# DMPAC_TOP_MAIN_0_DMPAC_REGS_DMPAC_REGS_CFG_IP_MMRS register map
Vendor: Texas Instruments
Registers are 32-bit, access not given, reset values left out (the file's numbers can be read two ways) unless marked. A register's access mark holds for its fields unless they carry their own. Offsets are as the file gives them; [hi:lo] are bit positions; {n}, {i} and the like mark numbered series.

## DMPAC_TOP_MAIN_0_DMPAC_REGS_DMPAC_REGS_CFG_IP_MMRS (part 2 of 2)
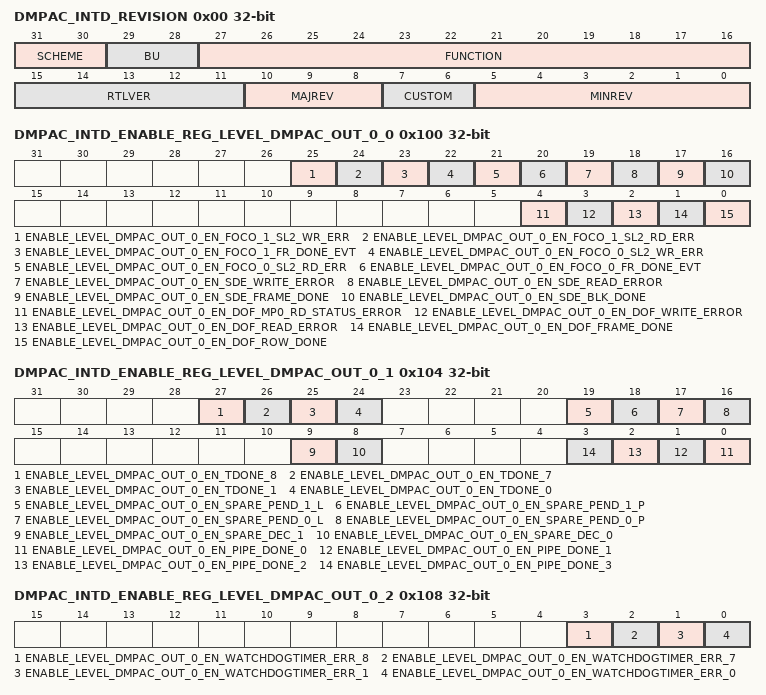
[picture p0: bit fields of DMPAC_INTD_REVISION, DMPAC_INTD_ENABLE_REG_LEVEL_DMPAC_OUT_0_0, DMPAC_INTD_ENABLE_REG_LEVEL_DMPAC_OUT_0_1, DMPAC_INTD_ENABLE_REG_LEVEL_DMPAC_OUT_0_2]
0x00 DMPAC_INTD_REVISION ro — Revision Register
  [31:30] SCHEME
  [29:28] BU
  [27:16] FUNCTION — Module ID
  [15:11] RTLVER — RTL revisions
  [10:8] MAJREV — MajorDMPAC_INTD_REVISION
  [7:6] CUSTOM — CustomDMPAC_INTD_REVISION
  [5:0] MINREV — MinorDMPAC_INTD_REVISION
0x10 DMPAC_INTD_EOI_REG rw — End of Interrupt Register The EOI register is used to re-trigger the pulse interrupt signal to ensure that any nested interrupt events are serviced. The software interrupt handler must write to the EOI register at the end of the current interrupt processing routine, so that new events can re-trigger the pulse interrupt signal again. For level interrupt signals the EOI register is not functional and must not be used.
  [7:0] EOI_VECTOR — End of Interrupt Vector
0x14 DMPAC_INTD_INTR_VECTOR_REG ro — Interrupt Vector Register
  [31:0] INTR_VECTOR
0x100 DMPAC_INTD_ENABLE_REG_LEVEL_DMPAC_OUT_0_0 — Enable Register 0
  [25] ENABLE_LEVEL_DMPAC_OUT_0_EN_FOCO_1_SL2_WR_ERR — Enable Set for level_dmpac_out_0_en_foco_1_sl2_wr_err (access RW1S)
  [24] ENABLE_LEVEL_DMPAC_OUT_0_EN_FOCO_1_SL2_RD_ERR — Enable Set for level_dmpac_out_0_en_foco_1_sl2_rd_err (access RW1S)
  [23] ENABLE_LEVEL_DMPAC_OUT_0_EN_FOCO_1_FR_DONE_EVT — Enable Set for level_dmpac_out_0_en_foco_1_fr_done_evt (access RW1S)
  [22] ENABLE_LEVEL_DMPAC_OUT_0_EN_FOCO_0_SL2_WR_ERR — Enable Set for level_dmpac_out_0_en_foco_0_sl2_wr_err (access RW1S)
  [21] ENABLE_LEVEL_DMPAC_OUT_0_EN_FOCO_0_SL2_RD_ERR — Enable Set for level_dmpac_out_0_en_foco_0_sl2_rd_err (access RW1S)
  [20] ENABLE_LEVEL_DMPAC_OUT_0_EN_FOCO_0_FR_DONE_EVT — Enable Set for level_dmpac_out_0_en_foco_0_fr_done_evt (access RW1S)
  [19] ENABLE_LEVEL_DMPAC_OUT_0_EN_SDE_WRITE_ERROR — Enable Set for level_dmpac_out_0_en_sde_write_error (access RW1S)
  [18] ENABLE_LEVEL_DMPAC_OUT_0_EN_SDE_READ_ERROR — Enable Set for level_dmpac_out_0_en_sde_read_error (access RW1S)
  [17] ENABLE_LEVEL_DMPAC_OUT_0_EN_SDE_FRAME_DONE — Enable Set for level_dmpac_out_0_en_sde_frame_done (access RW1S)
  [16] ENABLE_LEVEL_DMPAC_OUT_0_EN_SDE_BLK_DONE — Enable Set for level_dmpac_out_0_en_sde_blk_done (access RW1S)
  [4] ENABLE_LEVEL_DMPAC_OUT_0_EN_DOF_MP0_RD_STATUS_ERROR — Enable Set for level_dmpac_out_0_en_dof_mp0_rd_status_error (access RW1S)
  [3] ENABLE_LEVEL_DMPAC_OUT_0_EN_DOF_WRITE_ERROR — Enable Set for level_dmpac_out_0_en_dof_write_error (access RW1S)
  [2] ENABLE_LEVEL_DMPAC_OUT_0_EN_DOF_READ_ERROR — Enable Set for level_dmpac_out_0_en_dof_read_error (access RW1S)
  [1] ENABLE_LEVEL_DMPAC_OUT_0_EN_DOF_FRAME_DONE — Enable Set for level_dmpac_out_0_en_dof_frame_done (access RW1S)
  [0] ENABLE_LEVEL_DMPAC_OUT_0_EN_DOF_ROW_DONE — Enable Set for level_dmpac_out_0_en_dof_row_done (access RW1S)
0x104 DMPAC_INTD_ENABLE_REG_LEVEL_DMPAC_OUT_0_1 — Enable Register 1
  [27] ENABLE_LEVEL_DMPAC_OUT_0_EN_TDONE_8 — Enable Set for level_dmpac_out_0_en_tdone_8 (access RW1S)
  [26] ENABLE_LEVEL_DMPAC_OUT_0_EN_TDONE_7 — Enable Set for level_dmpac_out_0_en_tdone_7 (access RW1S)
  [25] ENABLE_LEVEL_DMPAC_OUT_0_EN_TDONE_1 — Enable Set for level_dmpac_out_0_en_tdone_1 (access RW1S)
  [24] ENABLE_LEVEL_DMPAC_OUT_0_EN_TDONE_0 — Enable Set for level_dmpac_out_0_en_tdone_0 (access RW1S)
  [19] ENABLE_LEVEL_DMPAC_OUT_0_EN_SPARE_PEND_1_L — Enable Set for level_dmpac_out_0_en_spare_pend_1_l (access RW1S)
  [18] ENABLE_LEVEL_DMPAC_OUT_0_EN_SPARE_PEND_1_P — Enable Set for level_dmpac_out_0_en_spare_pend_1_p (access RW1S)
  [17] ENABLE_LEVEL_DMPAC_OUT_0_EN_SPARE_PEND_0_L — Enable Set for level_dmpac_out_0_en_spare_pend_0_l (access RW1S)
  [16] ENABLE_LEVEL_DMPAC_OUT_0_EN_SPARE_PEND_0_P — Enable Set for level_dmpac_out_0_en_spare_pend_0_p (access RW1S)
  [9] ENABLE_LEVEL_DMPAC_OUT_0_EN_SPARE_DEC_1 — Enable Set for level_dmpac_out_0_en_spare_dec_1 (access RW1S)
  [8] ENABLE_LEVEL_DMPAC_OUT_0_EN_SPARE_DEC_0 — Enable Set for level_dmpac_out_0_en_spare_dec_0 (access RW1S)
  [n] ENABLE_LEVEL_DMPAC_OUT_0_EN_PIPE_DONE_{n} (n=0..3) — Enable Set for level_dmpac_out_0_en_pipe_done_{n} (access RW1S)
0x108 DMPAC_INTD_ENABLE_REG_LEVEL_DMPAC_OUT_0_2 — Enable Register 2
  [3] ENABLE_LEVEL_DMPAC_OUT_0_EN_WATCHDOGTIMER_ERR_8 — Enable Set for level_dmpac_out_0_en_watchdogtimer_err_8 (access RW1S)
  [2] ENABLE_LEVEL_DMPAC_OUT_0_EN_WATCHDOGTIMER_ERR_7 — Enable Set for level_dmpac_out_0_en_watchdogtimer_err_7 (access RW1S)
  [1] ENABLE_LEVEL_DMPAC_OUT_0_EN_WATCHDOGTIMER_ERR_1 — Enable Set for level_dmpac_out_0_en_watchdogtimer_err_1 (access RW1S)
  [0] ENABLE_LEVEL_DMPAC_OUT_0_EN_WATCHDOGTIMER_ERR_0 — Enable Set for level_dmpac_out_0_en_watchdogtimer_err_0 (access RW1S)
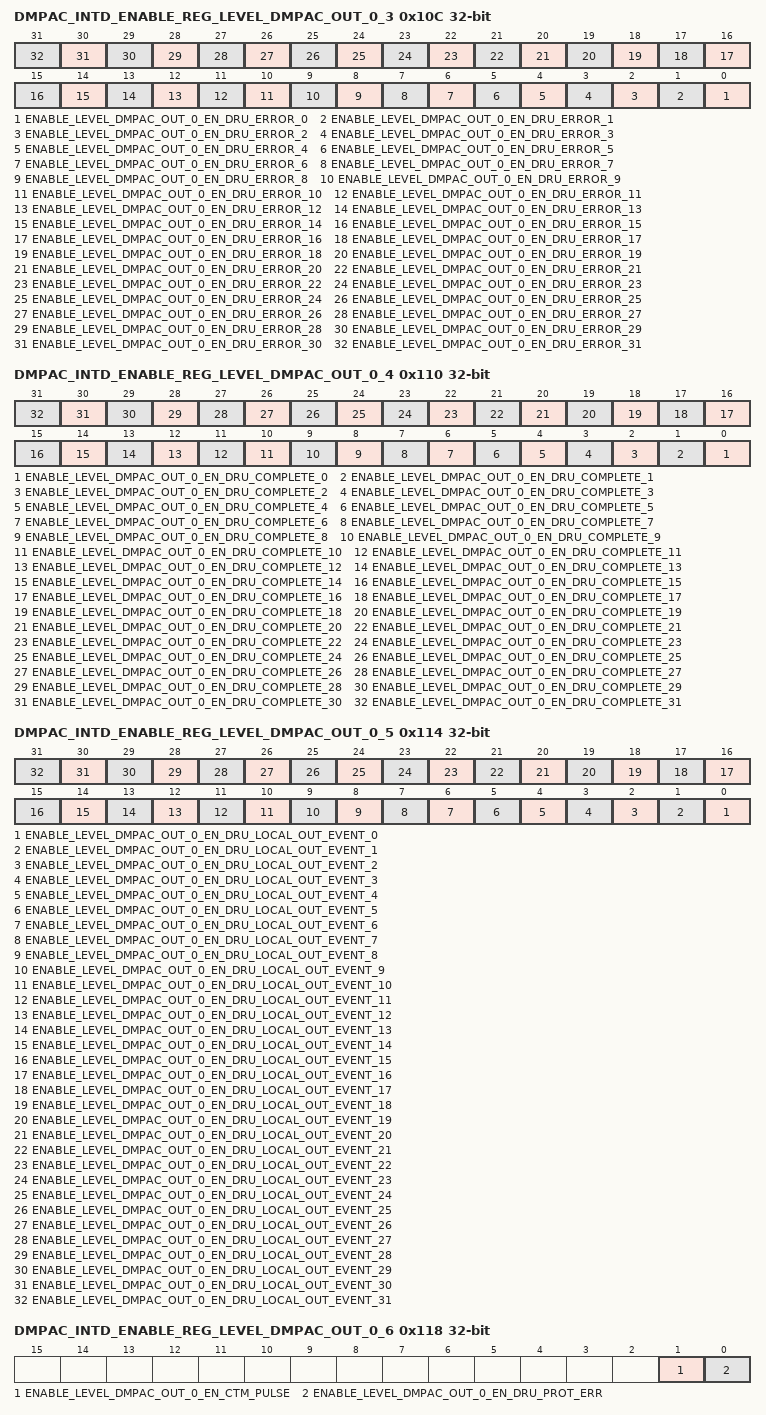
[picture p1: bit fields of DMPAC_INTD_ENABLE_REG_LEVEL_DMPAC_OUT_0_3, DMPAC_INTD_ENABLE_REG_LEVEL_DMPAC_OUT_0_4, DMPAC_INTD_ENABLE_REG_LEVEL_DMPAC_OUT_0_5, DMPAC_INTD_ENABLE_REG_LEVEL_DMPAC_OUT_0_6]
0x10C DMPAC_INTD_ENABLE_REG_LEVEL_DMPAC_OUT_0_3 — Enable Register 3
  [n] ENABLE_LEVEL_DMPAC_OUT_0_EN_DRU_ERROR_{n} (n=0..31) — Enable Set for level_dmpac_out_0_en_dru_error_{n} (access RW1S)
0x110 DMPAC_INTD_ENABLE_REG_LEVEL_DMPAC_OUT_0_4 — Enable Register 4
  [n] ENABLE_LEVEL_DMPAC_OUT_0_EN_DRU_COMPLETE_{n} (n=0..31) — Enable Set for level_dmpac_out_0_en_dru_complete_{n} (access RW1S)
0x114 DMPAC_INTD_ENABLE_REG_LEVEL_DMPAC_OUT_0_5 — Enable Register 5
  [n] ENABLE_LEVEL_DMPAC_OUT_0_EN_DRU_LOCAL_OUT_EVENT_{n} (n=0..31) — Enable Set for level_dmpac_out_0_en_dru_local_out_event_{n} (access RW1S)
0x118 DMPAC_INTD_ENABLE_REG_LEVEL_DMPAC_OUT_0_6 — Enable Register 6
  [1] ENABLE_LEVEL_DMPAC_OUT_0_EN_CTM_PULSE — Enable Set for level_dmpac_out_0_en_ctm_pulse (access RW1S)
  [0] ENABLE_LEVEL_DMPAC_OUT_0_EN_DRU_PROT_ERR — Enable Set for level_dmpac_out_0_en_dru_prot_err (access RW1S)
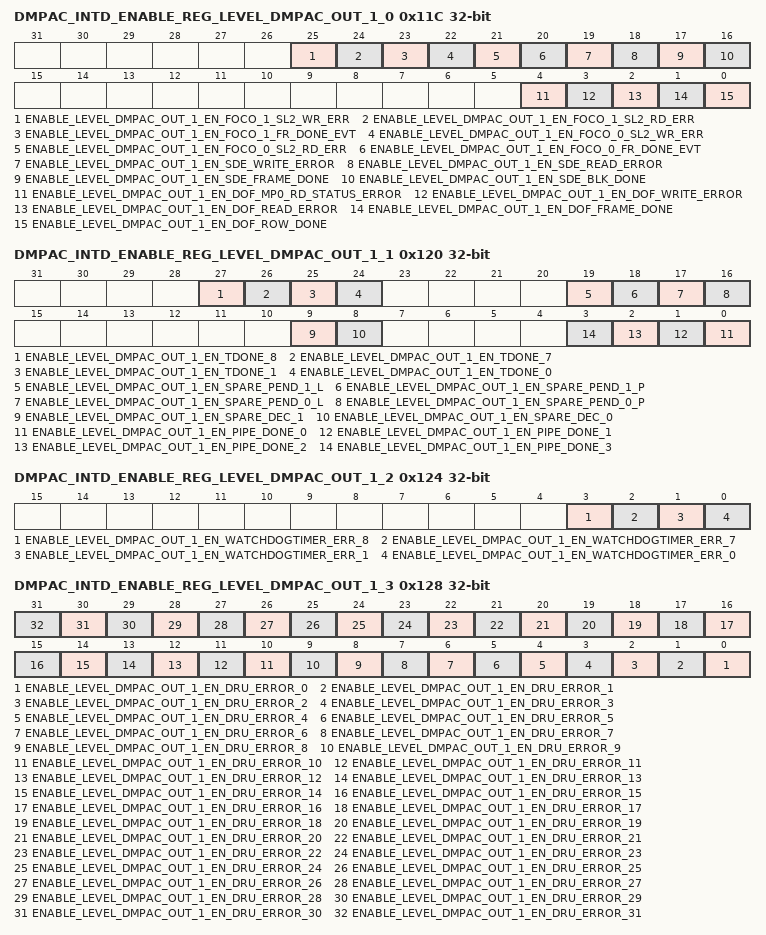
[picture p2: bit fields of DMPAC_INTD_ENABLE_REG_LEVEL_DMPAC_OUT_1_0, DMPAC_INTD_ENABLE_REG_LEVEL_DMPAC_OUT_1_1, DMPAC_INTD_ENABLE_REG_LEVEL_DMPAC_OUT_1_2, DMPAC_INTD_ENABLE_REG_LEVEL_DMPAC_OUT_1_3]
0x11C DMPAC_INTD_ENABLE_REG_LEVEL_DMPAC_OUT_1_0 — Enable Register 7
  [25] ENABLE_LEVEL_DMPAC_OUT_1_EN_FOCO_1_SL2_WR_ERR — Enable Set for level_dmpac_out_1_en_foco_1_sl2_wr_err (access RW1S)
  [24] ENABLE_LEVEL_DMPAC_OUT_1_EN_FOCO_1_SL2_RD_ERR — Enable Set for level_dmpac_out_1_en_foco_1_sl2_rd_err (access RW1S)
  [23] ENABLE_LEVEL_DMPAC_OUT_1_EN_FOCO_1_FR_DONE_EVT — Enable Set for level_dmpac_out_1_en_foco_1_fr_done_evt (access RW1S)
  [22] ENABLE_LEVEL_DMPAC_OUT_1_EN_FOCO_0_SL2_WR_ERR — Enable Set for level_dmpac_out_1_en_foco_0_sl2_wr_err (access RW1S)
  [21] ENABLE_LEVEL_DMPAC_OUT_1_EN_FOCO_0_SL2_RD_ERR — Enable Set for level_dmpac_out_1_en_foco_0_sl2_rd_err (access RW1S)
  [20] ENABLE_LEVEL_DMPAC_OUT_1_EN_FOCO_0_FR_DONE_EVT — Enable Set for level_dmpac_out_1_en_foco_0_fr_done_evt (access RW1S)
  [19] ENABLE_LEVEL_DMPAC_OUT_1_EN_SDE_WRITE_ERROR — Enable Set for level_dmpac_out_1_en_sde_write_error (access RW1S)
  [18] ENABLE_LEVEL_DMPAC_OUT_1_EN_SDE_READ_ERROR — Enable Set for level_dmpac_out_1_en_sde_read_error (access RW1S)
  [17] ENABLE_LEVEL_DMPAC_OUT_1_EN_SDE_FRAME_DONE — Enable Set for level_dmpac_out_1_en_sde_frame_done (access RW1S)
  [16] ENABLE_LEVEL_DMPAC_OUT_1_EN_SDE_BLK_DONE — Enable Set for level_dmpac_out_1_en_sde_blk_done (access RW1S)
  [4] ENABLE_LEVEL_DMPAC_OUT_1_EN_DOF_MP0_RD_STATUS_ERROR — Enable Set for level_dmpac_out_1_en_dof_mp0_rd_status_error (access RW1S)
  [3] ENABLE_LEVEL_DMPAC_OUT_1_EN_DOF_WRITE_ERROR — Enable Set for level_dmpac_out_1_en_dof_write_error (access RW1S)
  [2] ENABLE_LEVEL_DMPAC_OUT_1_EN_DOF_READ_ERROR — Enable Set for level_dmpac_out_1_en_dof_read_error (access RW1S)
  [1] ENABLE_LEVEL_DMPAC_OUT_1_EN_DOF_FRAME_DONE — Enable Set for level_dmpac_out_1_en_dof_frame_done (access RW1S)
  [0] ENABLE_LEVEL_DMPAC_OUT_1_EN_DOF_ROW_DONE — Enable Set for level_dmpac_out_1_en_dof_row_done (access RW1S)
0x120 DMPAC_INTD_ENABLE_REG_LEVEL_DMPAC_OUT_1_1 — Enable Register 8
  [27] ENABLE_LEVEL_DMPAC_OUT_1_EN_TDONE_8 — Enable Set for level_dmpac_out_1_en_tdone_8 (access RW1S)
  [26] ENABLE_LEVEL_DMPAC_OUT_1_EN_TDONE_7 — Enable Set for level_dmpac_out_1_en_tdone_7 (access RW1S)
  [25] ENABLE_LEVEL_DMPAC_OUT_1_EN_TDONE_1 — Enable Set for level_dmpac_out_1_en_tdone_1 (access RW1S)
  [24] ENABLE_LEVEL_DMPAC_OUT_1_EN_TDONE_0 — Enable Set for level_dmpac_out_1_en_tdone_0 (access RW1S)
  [19] ENABLE_LEVEL_DMPAC_OUT_1_EN_SPARE_PEND_1_L — Enable Set for level_dmpac_out_1_en_spare_pend_1_l (access RW1S)
  [18] ENABLE_LEVEL_DMPAC_OUT_1_EN_SPARE_PEND_1_P — Enable Set for level_dmpac_out_1_en_spare_pend_1_p (access RW1S)
  [17] ENABLE_LEVEL_DMPAC_OUT_1_EN_SPARE_PEND_0_L — Enable Set for level_dmpac_out_1_en_spare_pend_0_l (access RW1S)
  [16] ENABLE_LEVEL_DMPAC_OUT_1_EN_SPARE_PEND_0_P — Enable Set for level_dmpac_out_1_en_spare_pend_0_p (access RW1S)
  [9] ENABLE_LEVEL_DMPAC_OUT_1_EN_SPARE_DEC_1 — Enable Set for level_dmpac_out_1_en_spare_dec_1 (access RW1S)
  [8] ENABLE_LEVEL_DMPAC_OUT_1_EN_SPARE_DEC_0 — Enable Set for level_dmpac_out_1_en_spare_dec_0 (access RW1S)
  [n] ENABLE_LEVEL_DMPAC_OUT_1_EN_PIPE_DONE_{n} (n=0..3) — Enable Set for level_dmpac_out_1_en_pipe_done_{n} (access RW1S)
0x124 DMPAC_INTD_ENABLE_REG_LEVEL_DMPAC_OUT_1_2 — Enable Register 9
  [3] ENABLE_LEVEL_DMPAC_OUT_1_EN_WATCHDOGTIMER_ERR_8 — Enable Set for level_dmpac_out_1_en_watchdogtimer_err_8 (access RW1S)
  [2] ENABLE_LEVEL_DMPAC_OUT_1_EN_WATCHDOGTIMER_ERR_7 — Enable Set for level_dmpac_out_1_en_watchdogtimer_err_7 (access RW1S)
  [1] ENABLE_LEVEL_DMPAC_OUT_1_EN_WATCHDOGTIMER_ERR_1 — Enable Set for level_dmpac_out_1_en_watchdogtimer_err_1 (access RW1S)
  [0] ENABLE_LEVEL_DMPAC_OUT_1_EN_WATCHDOGTIMER_ERR_0 — Enable Set for level_dmpac_out_1_en_watchdogtimer_err_0 (access RW1S)
0x128 DMPAC_INTD_ENABLE_REG_LEVEL_DMPAC_OUT_1_3 — Enable Register 10
  [n] ENABLE_LEVEL_DMPAC_OUT_1_EN_DRU_ERROR_{n} (n=0..31) — Enable Set for level_dmpac_out_1_en_dru_error_{n} (access RW1S)
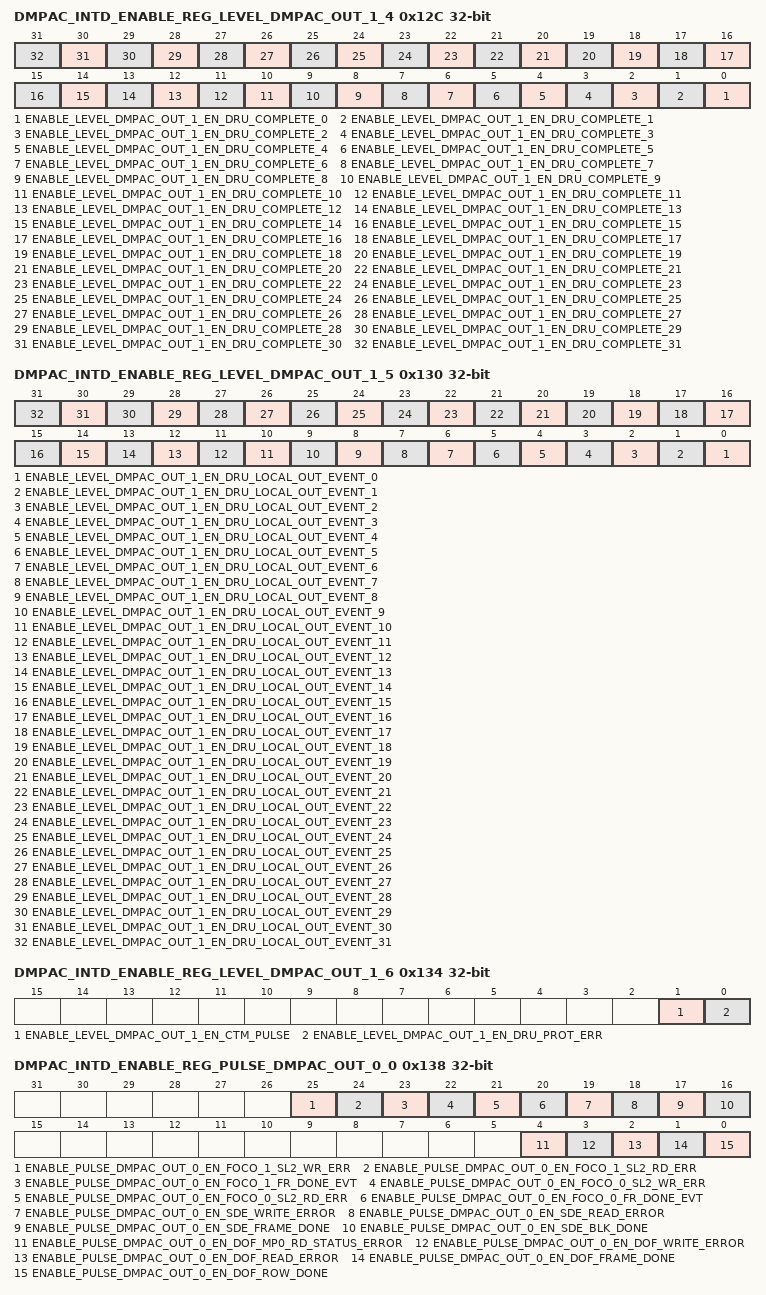
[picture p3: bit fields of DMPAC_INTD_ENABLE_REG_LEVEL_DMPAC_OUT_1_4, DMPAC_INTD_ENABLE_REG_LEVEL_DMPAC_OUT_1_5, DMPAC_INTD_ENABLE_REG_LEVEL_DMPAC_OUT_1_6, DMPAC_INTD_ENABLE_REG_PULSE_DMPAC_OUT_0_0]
0x12C DMPAC_INTD_ENABLE_REG_LEVEL_DMPAC_OUT_1_4 — Enable Register 11
  [n] ENABLE_LEVEL_DMPAC_OUT_1_EN_DRU_COMPLETE_{n} (n=0..31) — Enable Set for level_dmpac_out_1_en_dru_complete_{n} (access RW1S)
0x130 DMPAC_INTD_ENABLE_REG_LEVEL_DMPAC_OUT_1_5 — Enable Register 12
  [n] ENABLE_LEVEL_DMPAC_OUT_1_EN_DRU_LOCAL_OUT_EVENT_{n} (n=0..31) — Enable Set for level_dmpac_out_1_en_dru_local_out_event_{n} (access RW1S)
0x134 DMPAC_INTD_ENABLE_REG_LEVEL_DMPAC_OUT_1_6 — Enable Register 13
  [1] ENABLE_LEVEL_DMPAC_OUT_1_EN_CTM_PULSE — Enable Set for level_dmpac_out_1_en_ctm_pulse (access RW1S)
  [0] ENABLE_LEVEL_DMPAC_OUT_1_EN_DRU_PROT_ERR — Enable Set for level_dmpac_out_1_en_dru_prot_err (access RW1S)
0x138 DMPAC_INTD_ENABLE_REG_PULSE_DMPAC_OUT_0_0 — Enable Register 14
  [25] ENABLE_PULSE_DMPAC_OUT_0_EN_FOCO_1_SL2_WR_ERR — Enable Set for pulse_dmpac_out_0_en_foco_1_sl2_wr_err (access RW1S)
  [24] ENABLE_PULSE_DMPAC_OUT_0_EN_FOCO_1_SL2_RD_ERR — Enable Set for pulse_dmpac_out_0_en_foco_1_sl2_rd_err (access RW1S)
  [23] ENABLE_PULSE_DMPAC_OUT_0_EN_FOCO_1_FR_DONE_EVT — Enable Set for pulse_dmpac_out_0_en_foco_1_fr_done_evt (access RW1S)
  [22] ENABLE_PULSE_DMPAC_OUT_0_EN_FOCO_0_SL2_WR_ERR — Enable Set for pulse_dmpac_out_0_en_foco_0_sl2_wr_err (access RW1S)
  [21] ENABLE_PULSE_DMPAC_OUT_0_EN_FOCO_0_SL2_RD_ERR — Enable Set for pulse_dmpac_out_0_en_foco_0_sl2_rd_err (access RW1S)
  [20] ENABLE_PULSE_DMPAC_OUT_0_EN_FOCO_0_FR_DONE_EVT — Enable Set for pulse_dmpac_out_0_en_foco_0_fr_done_evt (access RW1S)
  [19] ENABLE_PULSE_DMPAC_OUT_0_EN_SDE_WRITE_ERROR — Enable Set for pulse_dmpac_out_0_en_sde_write_error (access RW1S)
  [18] ENABLE_PULSE_DMPAC_OUT_0_EN_SDE_READ_ERROR — Enable Set for pulse_dmpac_out_0_en_sde_read_error (access RW1S)
  [17] ENABLE_PULSE_DMPAC_OUT_0_EN_SDE_FRAME_DONE — Enable Set for pulse_dmpac_out_0_en_sde_frame_done (access RW1S)
  [16] ENABLE_PULSE_DMPAC_OUT_0_EN_SDE_BLK_DONE — Enable Set for pulse_dmpac_out_0_en_sde_blk_done (access RW1S)
  [4] ENABLE_PULSE_DMPAC_OUT_0_EN_DOF_MP0_RD_STATUS_ERROR — Enable Set for pulse_dmpac_out_0_en_dof_mp0_rd_status_error (access RW1S)
  [3] ENABLE_PULSE_DMPAC_OUT_0_EN_DOF_WRITE_ERROR — Enable Set for pulse_dmpac_out_0_en_dof_write_error (access RW1S)
  [2] ENABLE_PULSE_DMPAC_OUT_0_EN_DOF_READ_ERROR — Enable Set for pulse_dmpac_out_0_en_dof_read_error (access RW1S)
  [1] ENABLE_PULSE_DMPAC_OUT_0_EN_DOF_FRAME_DONE — Enable Set for pulse_dmpac_out_0_en_dof_frame_done (access RW1S)
  [0] ENABLE_PULSE_DMPAC_OUT_0_EN_DOF_ROW_DONE — Enable Set for pulse_dmpac_out_0_en_dof_row_done (access RW1S)
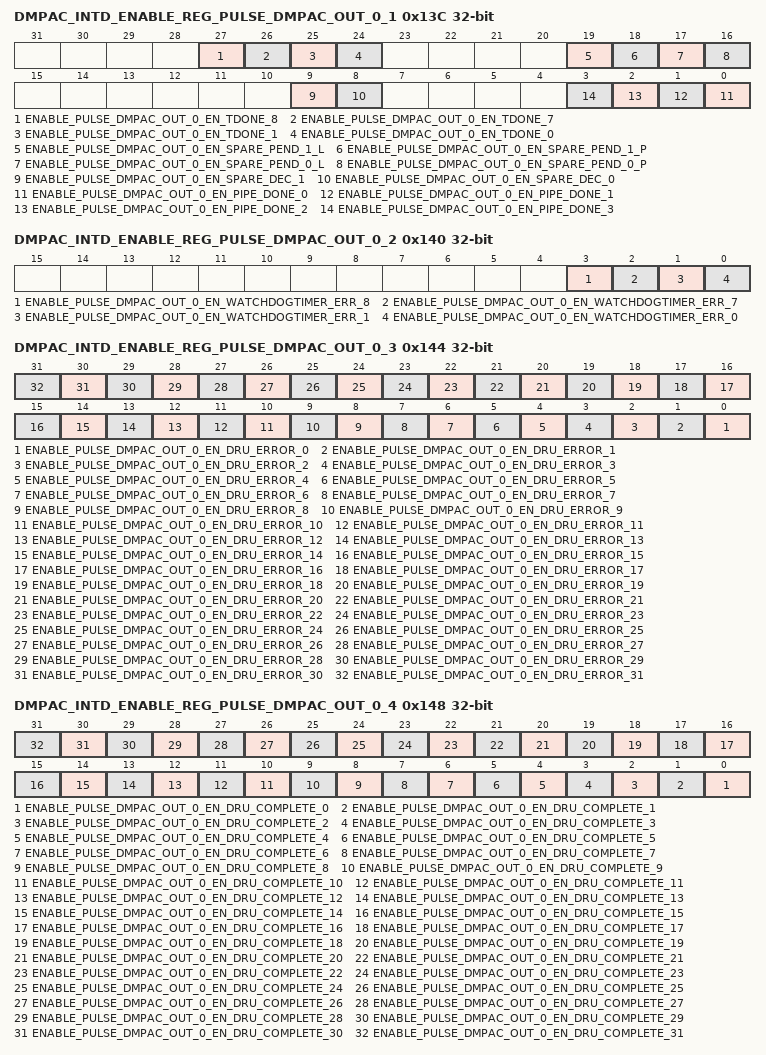
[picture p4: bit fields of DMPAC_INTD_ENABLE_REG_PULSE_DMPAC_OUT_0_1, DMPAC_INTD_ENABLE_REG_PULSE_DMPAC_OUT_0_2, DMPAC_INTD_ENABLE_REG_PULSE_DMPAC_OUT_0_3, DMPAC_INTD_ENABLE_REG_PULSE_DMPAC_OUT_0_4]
0x13C DMPAC_INTD_ENABLE_REG_PULSE_DMPAC_OUT_0_1 — Enable Register 15
  [27] ENABLE_PULSE_DMPAC_OUT_0_EN_TDONE_8 — Enable Set for pulse_dmpac_out_0_en_tdone_8 (access RW1S)
  [26] ENABLE_PULSE_DMPAC_OUT_0_EN_TDONE_7 — Enable Set for pulse_dmpac_out_0_en_tdone_7 (access RW1S)
  [25] ENABLE_PULSE_DMPAC_OUT_0_EN_TDONE_1 — Enable Set for pulse_dmpac_out_0_en_tdone_1 (access RW1S)
  [24] ENABLE_PULSE_DMPAC_OUT_0_EN_TDONE_0 — Enable Set for pulse_dmpac_out_0_en_tdone_0 (access RW1S)
  [19] ENABLE_PULSE_DMPAC_OUT_0_EN_SPARE_PEND_1_L — Enable Set for pulse_dmpac_out_0_en_spare_pend_1_l (access RW1S)
  [18] ENABLE_PULSE_DMPAC_OUT_0_EN_SPARE_PEND_1_P — Enable Set for pulse_dmpac_out_0_en_spare_pend_1_p (access RW1S)
  [17] ENABLE_PULSE_DMPAC_OUT_0_EN_SPARE_PEND_0_L — Enable Set for pulse_dmpac_out_0_en_spare_pend_0_l (access RW1S)
  [16] ENABLE_PULSE_DMPAC_OUT_0_EN_SPARE_PEND_0_P — Enable Set for pulse_dmpac_out_0_en_spare_pend_0_p (access RW1S)
  [9] ENABLE_PULSE_DMPAC_OUT_0_EN_SPARE_DEC_1 — Enable Set for pulse_dmpac_out_0_en_spare_dec_1 (access RW1S)
  [8] ENABLE_PULSE_DMPAC_OUT_0_EN_SPARE_DEC_0 — Enable Set for pulse_dmpac_out_0_en_spare_dec_0 (access RW1S)
  [n] ENABLE_PULSE_DMPAC_OUT_0_EN_PIPE_DONE_{n} (n=0..3) — Enable Set for pulse_dmpac_out_0_en_pipe_done_{n} (access RW1S)
0x140 DMPAC_INTD_ENABLE_REG_PULSE_DMPAC_OUT_0_2 — Enable Register 16
  [3] ENABLE_PULSE_DMPAC_OUT_0_EN_WATCHDOGTIMER_ERR_8 — Enable Set for pulse_dmpac_out_0_en_watchdogtimer_err_8 (access RW1S)
  [2] ENABLE_PULSE_DMPAC_OUT_0_EN_WATCHDOGTIMER_ERR_7 — Enable Set for pulse_dmpac_out_0_en_watchdogtimer_err_7 (access RW1S)
  [1] ENABLE_PULSE_DMPAC_OUT_0_EN_WATCHDOGTIMER_ERR_1 — Enable Set for pulse_dmpac_out_0_en_watchdogtimer_err_1 (access RW1S)
  [0] ENABLE_PULSE_DMPAC_OUT_0_EN_WATCHDOGTIMER_ERR_0 — Enable Set for pulse_dmpac_out_0_en_watchdogtimer_err_0 (access RW1S)
0x144 DMPAC_INTD_ENABLE_REG_PULSE_DMPAC_OUT_0_3 — Enable Register 17
  [n] ENABLE_PULSE_DMPAC_OUT_0_EN_DRU_ERROR_{n} (n=0..31) — Enable Set for pulse_dmpac_out_0_en_dru_error_{n} (access RW1S)
0x148 DMPAC_INTD_ENABLE_REG_PULSE_DMPAC_OUT_0_4 — Enable Register 18
  [n] ENABLE_PULSE_DMPAC_OUT_0_EN_DRU_COMPLETE_{n} (n=0..31) — Enable Set for pulse_dmpac_out_0_en_dru_complete_{n} (access RW1S)
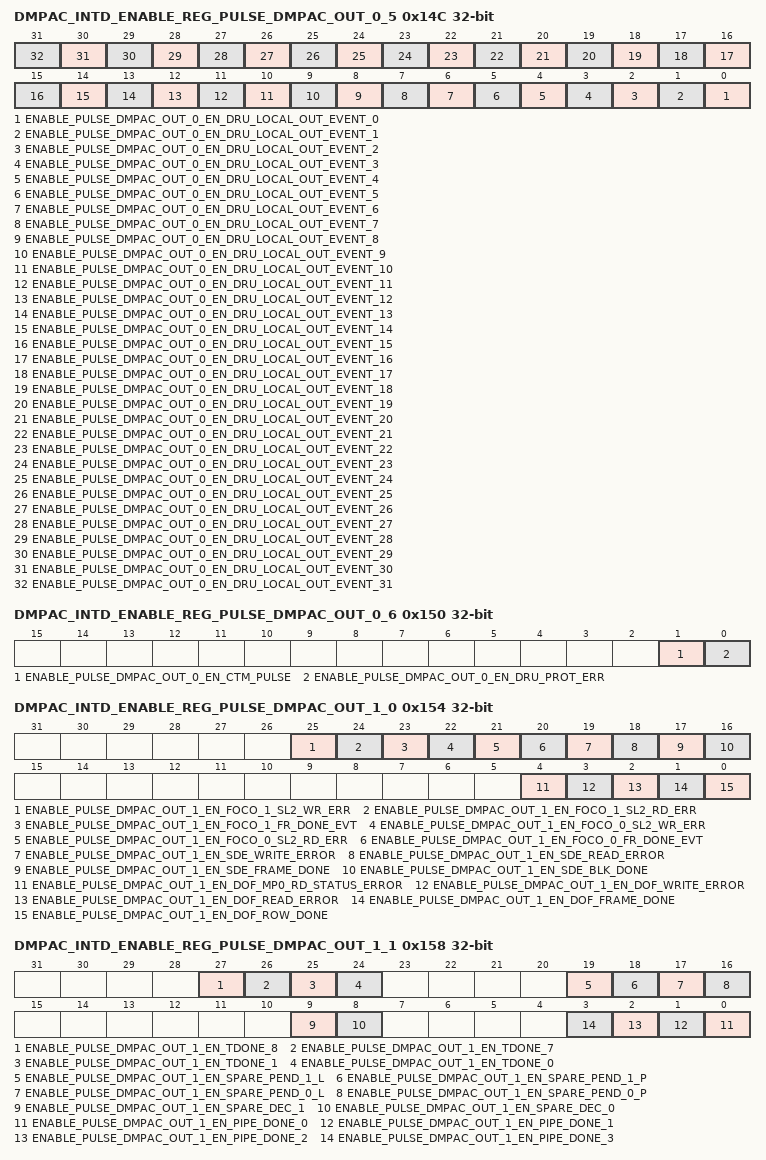
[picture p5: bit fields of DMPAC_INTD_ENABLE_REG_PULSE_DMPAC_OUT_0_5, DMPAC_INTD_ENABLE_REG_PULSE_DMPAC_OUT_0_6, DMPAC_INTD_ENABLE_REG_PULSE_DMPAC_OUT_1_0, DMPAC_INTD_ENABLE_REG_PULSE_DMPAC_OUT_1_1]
0x14C DMPAC_INTD_ENABLE_REG_PULSE_DMPAC_OUT_0_5 — Enable Register 19
  [n] ENABLE_PULSE_DMPAC_OUT_0_EN_DRU_LOCAL_OUT_EVENT_{n} (n=0..31) — Enable Set for pulse_dmpac_out_0_en_dru_local_out_event_{n} (access RW1S)
0x150 DMPAC_INTD_ENABLE_REG_PULSE_DMPAC_OUT_0_6 — Enable Register 20
  [1] ENABLE_PULSE_DMPAC_OUT_0_EN_CTM_PULSE — Enable Set for pulse_dmpac_out_0_en_ctm_pulse (access RW1S)
  [0] ENABLE_PULSE_DMPAC_OUT_0_EN_DRU_PROT_ERR — Enable Set for pulse_dmpac_out_0_en_dru_prot_err (access RW1S)
0x154 DMPAC_INTD_ENABLE_REG_PULSE_DMPAC_OUT_1_0 — Enable Register 21
  [25] ENABLE_PULSE_DMPAC_OUT_1_EN_FOCO_1_SL2_WR_ERR — Enable Set for pulse_dmpac_out_1_en_foco_1_sl2_wr_err (access RW1S)
  [24] ENABLE_PULSE_DMPAC_OUT_1_EN_FOCO_1_SL2_RD_ERR — Enable Set for pulse_dmpac_out_1_en_foco_1_sl2_rd_err (access RW1S)
  [23] ENABLE_PULSE_DMPAC_OUT_1_EN_FOCO_1_FR_DONE_EVT — Enable Set for pulse_dmpac_out_1_en_foco_1_fr_done_evt (access RW1S)
  [22] ENABLE_PULSE_DMPAC_OUT_1_EN_FOCO_0_SL2_WR_ERR — Enable Set for pulse_dmpac_out_1_en_foco_0_sl2_wr_err (access RW1S)
  [21] ENABLE_PULSE_DMPAC_OUT_1_EN_FOCO_0_SL2_RD_ERR — Enable Set for pulse_dmpac_out_1_en_foco_0_sl2_rd_err (access RW1S)
  [20] ENABLE_PULSE_DMPAC_OUT_1_EN_FOCO_0_FR_DONE_EVT — Enable Set for pulse_dmpac_out_1_en_foco_0_fr_done_evt (access RW1S)
  [19] ENABLE_PULSE_DMPAC_OUT_1_EN_SDE_WRITE_ERROR — Enable Set for pulse_dmpac_out_1_en_sde_write_error (access RW1S)
  [18] ENABLE_PULSE_DMPAC_OUT_1_EN_SDE_READ_ERROR — Enable Set for pulse_dmpac_out_1_en_sde_read_error (access RW1S)
  [17] ENABLE_PULSE_DMPAC_OUT_1_EN_SDE_FRAME_DONE — Enable Set for pulse_dmpac_out_1_en_sde_frame_done (access RW1S)
  [16] ENABLE_PULSE_DMPAC_OUT_1_EN_SDE_BLK_DONE — Enable Set for pulse_dmpac_out_1_en_sde_blk_done (access RW1S)
  [4] ENABLE_PULSE_DMPAC_OUT_1_EN_DOF_MP0_RD_STATUS_ERROR — Enable Set for pulse_dmpac_out_1_en_dof_mp0_rd_status_error (access RW1S)
  [3] ENABLE_PULSE_DMPAC_OUT_1_EN_DOF_WRITE_ERROR — Enable Set for pulse_dmpac_out_1_en_dof_write_error (access RW1S)
  [2] ENABLE_PULSE_DMPAC_OUT_1_EN_DOF_READ_ERROR — Enable Set for pulse_dmpac_out_1_en_dof_read_error (access RW1S)
  [1] ENABLE_PULSE_DMPAC_OUT_1_EN_DOF_FRAME_DONE — Enable Set for pulse_dmpac_out_1_en_dof_frame_done (access RW1S)
  [0] ENABLE_PULSE_DMPAC_OUT_1_EN_DOF_ROW_DONE — Enable Set for pulse_dmpac_out_1_en_dof_row_done (access RW1S)
0x158 DMPAC_INTD_ENABLE_REG_PULSE_DMPAC_OUT_1_1 — Enable Register 22
  [27] ENABLE_PULSE_DMPAC_OUT_1_EN_TDONE_8 — Enable Set for pulse_dmpac_out_1_en_tdone_8 (access RW1S)
  [26] ENABLE_PULSE_DMPAC_OUT_1_EN_TDONE_7 — Enable Set for pulse_dmpac_out_1_en_tdone_7 (access RW1S)
  [25] ENABLE_PULSE_DMPAC_OUT_1_EN_TDONE_1 — Enable Set for pulse_dmpac_out_1_en_tdone_1 (access RW1S)
  [24] ENABLE_PULSE_DMPAC_OUT_1_EN_TDONE_0 — Enable Set for pulse_dmpac_out_1_en_tdone_0 (access RW1S)
  [19] ENABLE_PULSE_DMPAC_OUT_1_EN_SPARE_PEND_1_L — Enable Set for pulse_dmpac_out_1_en_spare_pend_1_l (access RW1S)
  [18] ENABLE_PULSE_DMPAC_OUT_1_EN_SPARE_PEND_1_P — Enable Set for pulse_dmpac_out_1_en_spare_pend_1_p (access RW1S)
  [17] ENABLE_PULSE_DMPAC_OUT_1_EN_SPARE_PEND_0_L — Enable Set for pulse_dmpac_out_1_en_spare_pend_0_l (access RW1S)
  [16] ENABLE_PULSE_DMPAC_OUT_1_EN_SPARE_PEND_0_P — Enable Set for pulse_dmpac_out_1_en_spare_pend_0_p (access RW1S)
  [9] ENABLE_PULSE_DMPAC_OUT_1_EN_SPARE_DEC_1 — Enable Set for pulse_dmpac_out_1_en_spare_dec_1 (access RW1S)
  [8] ENABLE_PULSE_DMPAC_OUT_1_EN_SPARE_DEC_0 — Enable Set for pulse_dmpac_out_1_en_spare_dec_0 (access RW1S)
  [n] ENABLE_PULSE_DMPAC_OUT_1_EN_PIPE_DONE_{n} (n=0..3) — Enable Set for pulse_dmpac_out_1_en_pipe_done_{n} (access RW1S)
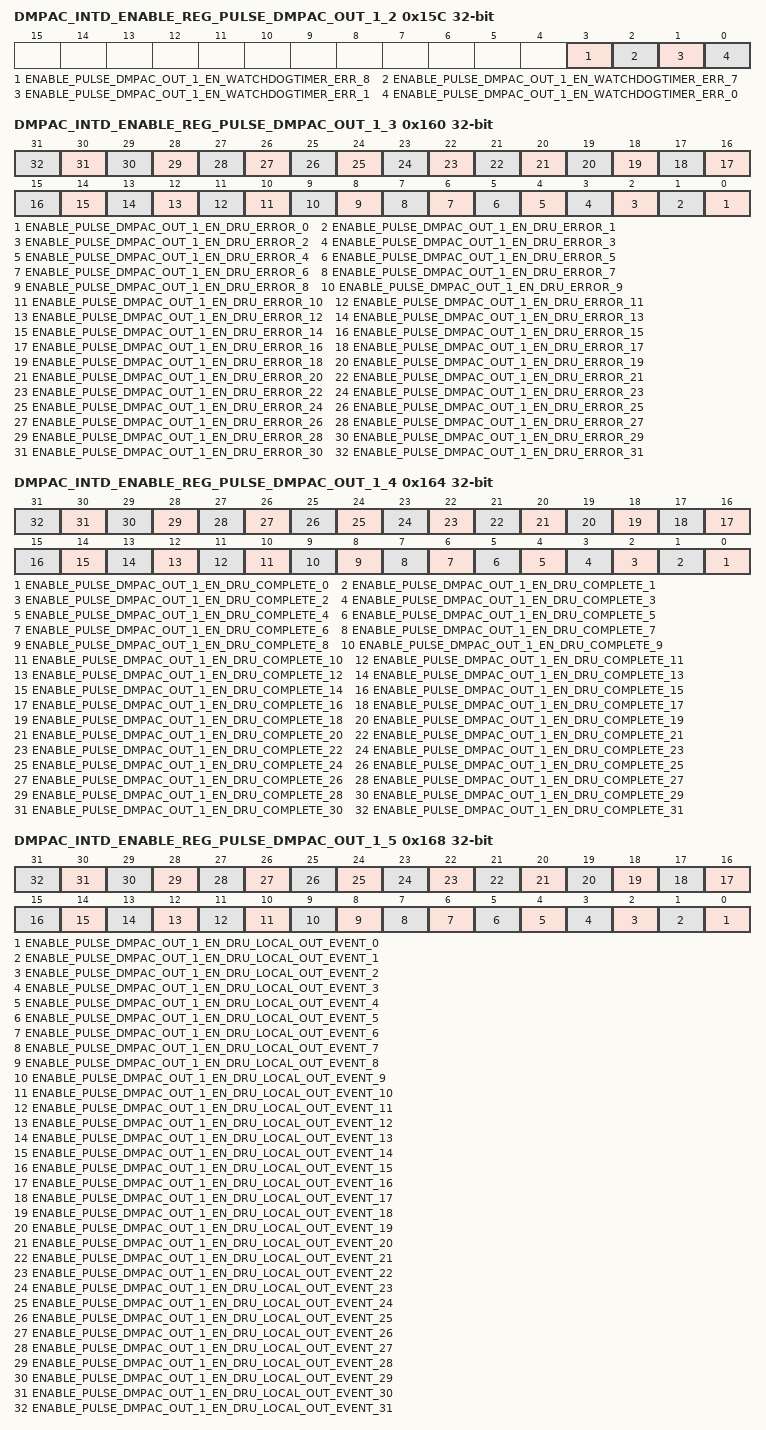
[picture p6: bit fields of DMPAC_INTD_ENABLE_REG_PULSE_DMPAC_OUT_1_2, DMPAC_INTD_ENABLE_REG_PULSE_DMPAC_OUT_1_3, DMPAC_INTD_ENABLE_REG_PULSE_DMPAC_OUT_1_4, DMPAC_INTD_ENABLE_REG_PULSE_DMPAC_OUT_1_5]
0x15C DMPAC_INTD_ENABLE_REG_PULSE_DMPAC_OUT_1_2 — Enable Register 23
  [3] ENABLE_PULSE_DMPAC_OUT_1_EN_WATCHDOGTIMER_ERR_8 — Enable Set for pulse_dmpac_out_1_en_watchdogtimer_err_8 (access RW1S)
  [2] ENABLE_PULSE_DMPAC_OUT_1_EN_WATCHDOGTIMER_ERR_7 — Enable Set for pulse_dmpac_out_1_en_watchdogtimer_err_7 (access RW1S)
  [1] ENABLE_PULSE_DMPAC_OUT_1_EN_WATCHDOGTIMER_ERR_1 — Enable Set for pulse_dmpac_out_1_en_watchdogtimer_err_1 (access RW1S)
  [0] ENABLE_PULSE_DMPAC_OUT_1_EN_WATCHDOGTIMER_ERR_0 — Enable Set for pulse_dmpac_out_1_en_watchdogtimer_err_0 (access RW1S)
0x160 DMPAC_INTD_ENABLE_REG_PULSE_DMPAC_OUT_1_3 — Enable Register 24
  [n] ENABLE_PULSE_DMPAC_OUT_1_EN_DRU_ERROR_{n} (n=0..31) — Enable Set for pulse_dmpac_out_1_en_dru_error_{n} (access RW1S)
0x164 DMPAC_INTD_ENABLE_REG_PULSE_DMPAC_OUT_1_4 — Enable Register 25
  [n] ENABLE_PULSE_DMPAC_OUT_1_EN_DRU_COMPLETE_{n} (n=0..31) — Enable Set for pulse_dmpac_out_1_en_dru_complete_{n} (access RW1S)
0x168 DMPAC_INTD_ENABLE_REG_PULSE_DMPAC_OUT_1_5 — Enable Register 26
  [n] ENABLE_PULSE_DMPAC_OUT_1_EN_DRU_LOCAL_OUT_EVENT_{n} (n=0..31) — Enable Set for pulse_dmpac_out_1_en_dru_local_out_event_{n} (access RW1S)
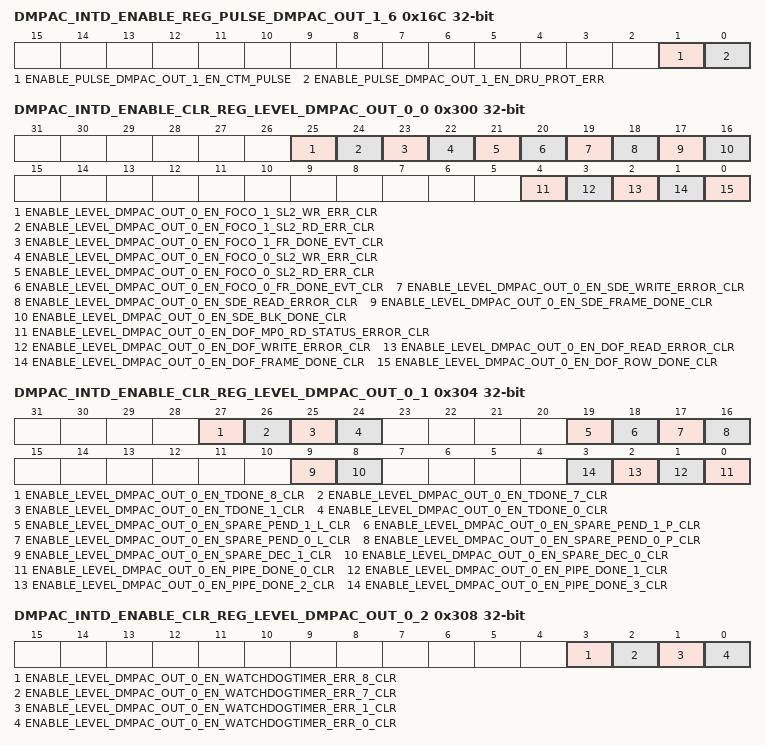
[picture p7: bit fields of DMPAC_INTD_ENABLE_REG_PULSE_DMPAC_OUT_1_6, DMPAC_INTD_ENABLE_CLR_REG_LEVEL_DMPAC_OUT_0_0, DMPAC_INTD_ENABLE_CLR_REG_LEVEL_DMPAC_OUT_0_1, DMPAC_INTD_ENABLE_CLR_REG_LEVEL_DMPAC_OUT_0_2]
0x16C DMPAC_INTD_ENABLE_REG_PULSE_DMPAC_OUT_1_6 — Enable Register 27
  [1] ENABLE_PULSE_DMPAC_OUT_1_EN_CTM_PULSE — Enable Set for pulse_dmpac_out_1_en_ctm_pulse (access RW1S)
  [0] ENABLE_PULSE_DMPAC_OUT_1_EN_DRU_PROT_ERR — Enable Set for pulse_dmpac_out_1_en_dru_prot_err (access RW1S)
0x300 DMPAC_INTD_ENABLE_CLR_REG_LEVEL_DMPAC_OUT_0_0 — Enable Clear Register 0
  [25] ENABLE_LEVEL_DMPAC_OUT_0_EN_FOCO_1_SL2_WR_ERR_CLR — Enable Clear for level_dmpac_out_0_en_foco_1_sl2_wr_err (access RW1C)
  [24] ENABLE_LEVEL_DMPAC_OUT_0_EN_FOCO_1_SL2_RD_ERR_CLR — Enable Clear for level_dmpac_out_0_en_foco_1_sl2_rd_err (access RW1C)
  [23] ENABLE_LEVEL_DMPAC_OUT_0_EN_FOCO_1_FR_DONE_EVT_CLR — Enable Clear for level_dmpac_out_0_en_foco_1_fr_done_evt (access RW1C)
  [22] ENABLE_LEVEL_DMPAC_OUT_0_EN_FOCO_0_SL2_WR_ERR_CLR — Enable Clear for level_dmpac_out_0_en_foco_0_sl2_wr_err (access RW1C)
  [21] ENABLE_LEVEL_DMPAC_OUT_0_EN_FOCO_0_SL2_RD_ERR_CLR — Enable Clear for level_dmpac_out_0_en_foco_0_sl2_rd_err (access RW1C)
  [20] ENABLE_LEVEL_DMPAC_OUT_0_EN_FOCO_0_FR_DONE_EVT_CLR — Enable Clear for level_dmpac_out_0_en_foco_0_fr_done_evt (access RW1C)
  [19] ENABLE_LEVEL_DMPAC_OUT_0_EN_SDE_WRITE_ERROR_CLR — Enable Clear for level_dmpac_out_0_en_sde_write_error (access RW1C)
  [18] ENABLE_LEVEL_DMPAC_OUT_0_EN_SDE_READ_ERROR_CLR — Enable Clear for level_dmpac_out_0_en_sde_read_error (access RW1C)
  [17] ENABLE_LEVEL_DMPAC_OUT_0_EN_SDE_FRAME_DONE_CLR — Enable Clear for level_dmpac_out_0_en_sde_frame_done (access RW1C)
  [16] ENABLE_LEVEL_DMPAC_OUT_0_EN_SDE_BLK_DONE_CLR — Enable Clear for level_dmpac_out_0_en_sde_blk_done (access RW1C)
  [4] ENABLE_LEVEL_DMPAC_OUT_0_EN_DOF_MP0_RD_STATUS_ERROR_CLR — Enable Clear for level_dmpac_out_0_en_dof_mp0_rd_status_error (access RW1C)
  [3] ENABLE_LEVEL_DMPAC_OUT_0_EN_DOF_WRITE_ERROR_CLR — Enable Clear for level_dmpac_out_0_en_dof_write_error (access RW1C)
  [2] ENABLE_LEVEL_DMPAC_OUT_0_EN_DOF_READ_ERROR_CLR — Enable Clear for level_dmpac_out_0_en_dof_read_error (access RW1C)
  [1] ENABLE_LEVEL_DMPAC_OUT_0_EN_DOF_FRAME_DONE_CLR — Enable Clear for level_dmpac_out_0_en_dof_frame_done (access RW1C)
  [0] ENABLE_LEVEL_DMPAC_OUT_0_EN_DOF_ROW_DONE_CLR — Enable Clear for level_dmpac_out_0_en_dof_row_done (access RW1C)
0x304 DMPAC_INTD_ENABLE_CLR_REG_LEVEL_DMPAC_OUT_0_1 — Enable Clear Register 1
  [27] ENABLE_LEVEL_DMPAC_OUT_0_EN_TDONE_8_CLR — Enable Clear for level_dmpac_out_0_en_tdone_8 (access RW1C)
  [26] ENABLE_LEVEL_DMPAC_OUT_0_EN_TDONE_7_CLR — Enable Clear for level_dmpac_out_0_en_tdone_7 (access RW1C)
  [25] ENABLE_LEVEL_DMPAC_OUT_0_EN_TDONE_1_CLR — Enable Clear for level_dmpac_out_0_en_tdone_1 (access RW1C)
  [24] ENABLE_LEVEL_DMPAC_OUT_0_EN_TDONE_0_CLR — Enable Clear for level_dmpac_out_0_en_tdone_0 (access RW1C)
  [19] ENABLE_LEVEL_DMPAC_OUT_0_EN_SPARE_PEND_1_L_CLR — Enable Clear for level_dmpac_out_0_en_spare_pend_1_l (access RW1C)
  [18] ENABLE_LEVEL_DMPAC_OUT_0_EN_SPARE_PEND_1_P_CLR — Enable Clear for level_dmpac_out_0_en_spare_pend_1_p (access RW1C)
  [17] ENABLE_LEVEL_DMPAC_OUT_0_EN_SPARE_PEND_0_L_CLR — Enable Clear for level_dmpac_out_0_en_spare_pend_0_l (access RW1C)
  [16] ENABLE_LEVEL_DMPAC_OUT_0_EN_SPARE_PEND_0_P_CLR — Enable Clear for level_dmpac_out_0_en_spare_pend_0_p (access RW1C)
  [9] ENABLE_LEVEL_DMPAC_OUT_0_EN_SPARE_DEC_1_CLR — Enable Clear for level_dmpac_out_0_en_spare_dec_1 (access RW1C)
  [8] ENABLE_LEVEL_DMPAC_OUT_0_EN_SPARE_DEC_0_CLR — Enable Clear for level_dmpac_out_0_en_spare_dec_0 (access RW1C)
  [n] ENABLE_LEVEL_DMPAC_OUT_0_EN_PIPE_DONE_{n}_CLR (n=0..3) — Enable Clear for level_dmpac_out_0_en_pipe_done_{n} (access RW1C)
0x308 DMPAC_INTD_ENABLE_CLR_REG_LEVEL_DMPAC_OUT_0_2 — Enable Clear Register 2
  [3] ENABLE_LEVEL_DMPAC_OUT_0_EN_WATCHDOGTIMER_ERR_8_CLR — Enable Clear for level_dmpac_out_0_en_watchdogtimer_err_8 (access RW1C)
  [2] ENABLE_LEVEL_DMPAC_OUT_0_EN_WATCHDOGTIMER_ERR_7_CLR — Enable Clear for level_dmpac_out_0_en_watchdogtimer_err_7 (access RW1C)
  [1] ENABLE_LEVEL_DMPAC_OUT_0_EN_WATCHDOGTIMER_ERR_1_CLR — Enable Clear for level_dmpac_out_0_en_watchdogtimer_err_1 (access RW1C)
  [0] ENABLE_LEVEL_DMPAC_OUT_0_EN_WATCHDOGTIMER_ERR_0_CLR — Enable Clear for level_dmpac_out_0_en_watchdogtimer_err_0 (access RW1C)
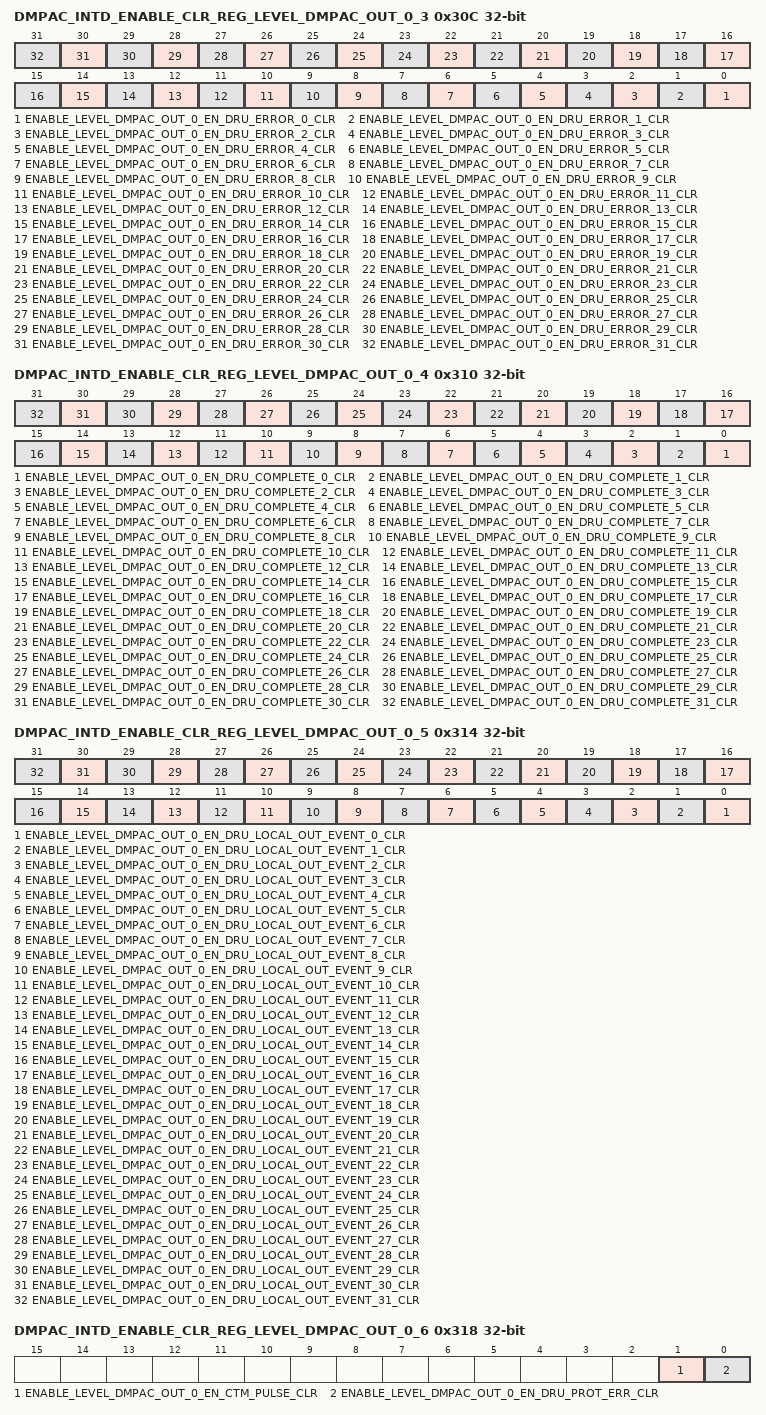
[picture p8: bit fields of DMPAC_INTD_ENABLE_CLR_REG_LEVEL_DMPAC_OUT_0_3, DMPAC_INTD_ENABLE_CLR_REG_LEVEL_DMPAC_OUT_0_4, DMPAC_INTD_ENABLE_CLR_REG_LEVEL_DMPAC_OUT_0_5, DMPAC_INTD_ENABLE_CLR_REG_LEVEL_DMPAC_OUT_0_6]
0x30C DMPAC_INTD_ENABLE_CLR_REG_LEVEL_DMPAC_OUT_0_3 — Enable Clear Register 3
  [n] ENABLE_LEVEL_DMPAC_OUT_0_EN_DRU_ERROR_{n}_CLR (n=0..31) — Enable Clear for level_dmpac_out_0_en_dru_error_{n} (access RW1C)
0x310 DMPAC_INTD_ENABLE_CLR_REG_LEVEL_DMPAC_OUT_0_4 — Enable Clear Register 4
  [n] ENABLE_LEVEL_DMPAC_OUT_0_EN_DRU_COMPLETE_{n}_CLR (n=0..31) — Enable Clear for level_dmpac_out_0_en_dru_complete_{n} (access RW1C)
0x314 DMPAC_INTD_ENABLE_CLR_REG_LEVEL_DMPAC_OUT_0_5 — Enable Clear Register 5
  [n] ENABLE_LEVEL_DMPAC_OUT_0_EN_DRU_LOCAL_OUT_EVENT_{n}_CLR (n=0..31) — Enable Clear for level_dmpac_out_0_en_dru_local_out_event_{n} (access RW1C)
0x318 DMPAC_INTD_ENABLE_CLR_REG_LEVEL_DMPAC_OUT_0_6 — Enable Clear Register 6
  [1] ENABLE_LEVEL_DMPAC_OUT_0_EN_CTM_PULSE_CLR — Enable Clear for level_dmpac_out_0_en_ctm_pulse (access RW1C)
  [0] ENABLE_LEVEL_DMPAC_OUT_0_EN_DRU_PROT_ERR_CLR — Enable Clear for level_dmpac_out_0_en_dru_prot_err (access RW1C)
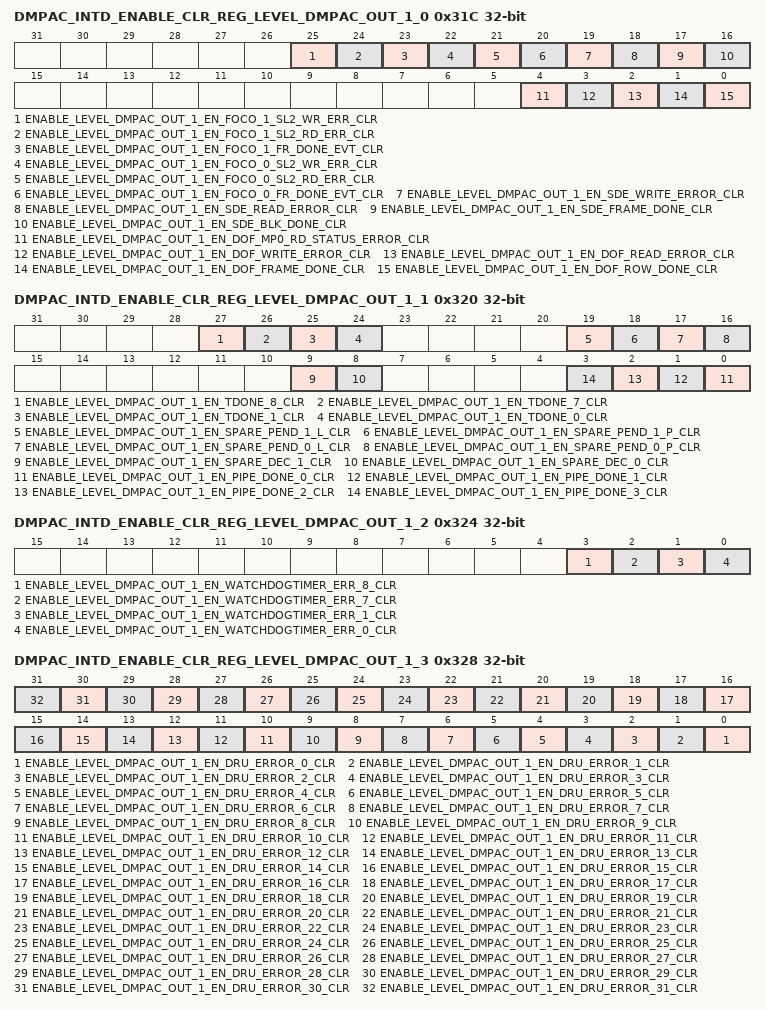
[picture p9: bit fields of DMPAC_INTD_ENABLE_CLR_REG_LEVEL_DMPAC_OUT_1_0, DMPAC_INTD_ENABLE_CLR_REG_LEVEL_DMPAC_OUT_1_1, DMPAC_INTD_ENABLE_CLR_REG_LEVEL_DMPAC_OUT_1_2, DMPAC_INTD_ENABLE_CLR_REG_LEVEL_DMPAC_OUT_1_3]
0x31C DMPAC_INTD_ENABLE_CLR_REG_LEVEL_DMPAC_OUT_1_0 — Enable Clear Register 7
  [25] ENABLE_LEVEL_DMPAC_OUT_1_EN_FOCO_1_SL2_WR_ERR_CLR — Enable Clear for level_dmpac_out_1_en_foco_1_sl2_wr_err (access RW1C)
  [24] ENABLE_LEVEL_DMPAC_OUT_1_EN_FOCO_1_SL2_RD_ERR_CLR — Enable Clear for level_dmpac_out_1_en_foco_1_sl2_rd_err (access RW1C)
  [23] ENABLE_LEVEL_DMPAC_OUT_1_EN_FOCO_1_FR_DONE_EVT_CLR — Enable Clear for level_dmpac_out_1_en_foco_1_fr_done_evt (access RW1C)
  [22] ENABLE_LEVEL_DMPAC_OUT_1_EN_FOCO_0_SL2_WR_ERR_CLR — Enable Clear for level_dmpac_out_1_en_foco_0_sl2_wr_err (access RW1C)
  [21] ENABLE_LEVEL_DMPAC_OUT_1_EN_FOCO_0_SL2_RD_ERR_CLR — Enable Clear for level_dmpac_out_1_en_foco_0_sl2_rd_err (access RW1C)
  [20] ENABLE_LEVEL_DMPAC_OUT_1_EN_FOCO_0_FR_DONE_EVT_CLR — Enable Clear for level_dmpac_out_1_en_foco_0_fr_done_evt (access RW1C)
  [19] ENABLE_LEVEL_DMPAC_OUT_1_EN_SDE_WRITE_ERROR_CLR — Enable Clear for level_dmpac_out_1_en_sde_write_error (access RW1C)
  [18] ENABLE_LEVEL_DMPAC_OUT_1_EN_SDE_READ_ERROR_CLR — Enable Clear for level_dmpac_out_1_en_sde_read_error (access RW1C)
  [17] ENABLE_LEVEL_DMPAC_OUT_1_EN_SDE_FRAME_DONE_CLR — Enable Clear for level_dmpac_out_1_en_sde_frame_done (access RW1C)
  [16] ENABLE_LEVEL_DMPAC_OUT_1_EN_SDE_BLK_DONE_CLR — Enable Clear for level_dmpac_out_1_en_sde_blk_done (access RW1C)
  [4] ENABLE_LEVEL_DMPAC_OUT_1_EN_DOF_MP0_RD_STATUS_ERROR_CLR — Enable Clear for level_dmpac_out_1_en_dof_mp0_rd_status_error (access RW1C)
  [3] ENABLE_LEVEL_DMPAC_OUT_1_EN_DOF_WRITE_ERROR_CLR — Enable Clear for level_dmpac_out_1_en_dof_write_error (access RW1C)
  [2] ENABLE_LEVEL_DMPAC_OUT_1_EN_DOF_READ_ERROR_CLR — Enable Clear for level_dmpac_out_1_en_dof_read_error (access RW1C)
  [1] ENABLE_LEVEL_DMPAC_OUT_1_EN_DOF_FRAME_DONE_CLR — Enable Clear for level_dmpac_out_1_en_dof_frame_done (access RW1C)
  [0] ENABLE_LEVEL_DMPAC_OUT_1_EN_DOF_ROW_DONE_CLR — Enable Clear for level_dmpac_out_1_en_dof_row_done (access RW1C)
0x320 DMPAC_INTD_ENABLE_CLR_REG_LEVEL_DMPAC_OUT_1_1 — Enable Clear Register 8
  [27] ENABLE_LEVEL_DMPAC_OUT_1_EN_TDONE_8_CLR — Enable Clear for level_dmpac_out_1_en_tdone_8 (access RW1C)
  [26] ENABLE_LEVEL_DMPAC_OUT_1_EN_TDONE_7_CLR — Enable Clear for level_dmpac_out_1_en_tdone_7 (access RW1C)
  [25] ENABLE_LEVEL_DMPAC_OUT_1_EN_TDONE_1_CLR — Enable Clear for level_dmpac_out_1_en_tdone_1 (access RW1C)
  [24] ENABLE_LEVEL_DMPAC_OUT_1_EN_TDONE_0_CLR — Enable Clear for level_dmpac_out_1_en_tdone_0 (access RW1C)
  [19] ENABLE_LEVEL_DMPAC_OUT_1_EN_SPARE_PEND_1_L_CLR — Enable Clear for level_dmpac_out_1_en_spare_pend_1_l (access RW1C)
  [18] ENABLE_LEVEL_DMPAC_OUT_1_EN_SPARE_PEND_1_P_CLR — Enable Clear for level_dmpac_out_1_en_spare_pend_1_p (access RW1C)
  [17] ENABLE_LEVEL_DMPAC_OUT_1_EN_SPARE_PEND_0_L_CLR — Enable Clear for level_dmpac_out_1_en_spare_pend_0_l (access RW1C)
  [16] ENABLE_LEVEL_DMPAC_OUT_1_EN_SPARE_PEND_0_P_CLR — Enable Clear for level_dmpac_out_1_en_spare_pend_0_p (access RW1C)
  [9] ENABLE_LEVEL_DMPAC_OUT_1_EN_SPARE_DEC_1_CLR — Enable Clear for level_dmpac_out_1_en_spare_dec_1 (access RW1C)
  [8] ENABLE_LEVEL_DMPAC_OUT_1_EN_SPARE_DEC_0_CLR — Enable Clear for level_dmpac_out_1_en_spare_dec_0 (access RW1C)
  [n] ENABLE_LEVEL_DMPAC_OUT_1_EN_PIPE_DONE_{n}_CLR (n=0..3) — Enable Clear for level_dmpac_out_1_en_pipe_done_{n} (access RW1C)
0x324 DMPAC_INTD_ENABLE_CLR_REG_LEVEL_DMPAC_OUT_1_2 — Enable Clear Register 9
  [3] ENABLE_LEVEL_DMPAC_OUT_1_EN_WATCHDOGTIMER_ERR_8_CLR — Enable Clear for level_dmpac_out_1_en_watchdogtimer_err_8 (access RW1C)
  [2] ENABLE_LEVEL_DMPAC_OUT_1_EN_WATCHDOGTIMER_ERR_7_CLR — Enable Clear for level_dmpac_out_1_en_watchdogtimer_err_7 (access RW1C)
  [1] ENABLE_LEVEL_DMPAC_OUT_1_EN_WATCHDOGTIMER_ERR_1_CLR — Enable Clear for level_dmpac_out_1_en_watchdogtimer_err_1 (access RW1C)
  [0] ENABLE_LEVEL_DMPAC_OUT_1_EN_WATCHDOGTIMER_ERR_0_CLR — Enable Clear for level_dmpac_out_1_en_watchdogtimer_err_0 (access RW1C)
0x328 DMPAC_INTD_ENABLE_CLR_REG_LEVEL_DMPAC_OUT_1_3 — Enable Clear Register 10
  [n] ENABLE_LEVEL_DMPAC_OUT_1_EN_DRU_ERROR_{n}_CLR (n=0..31) — Enable Clear for level_dmpac_out_1_en_dru_error_{n} (access RW1C)
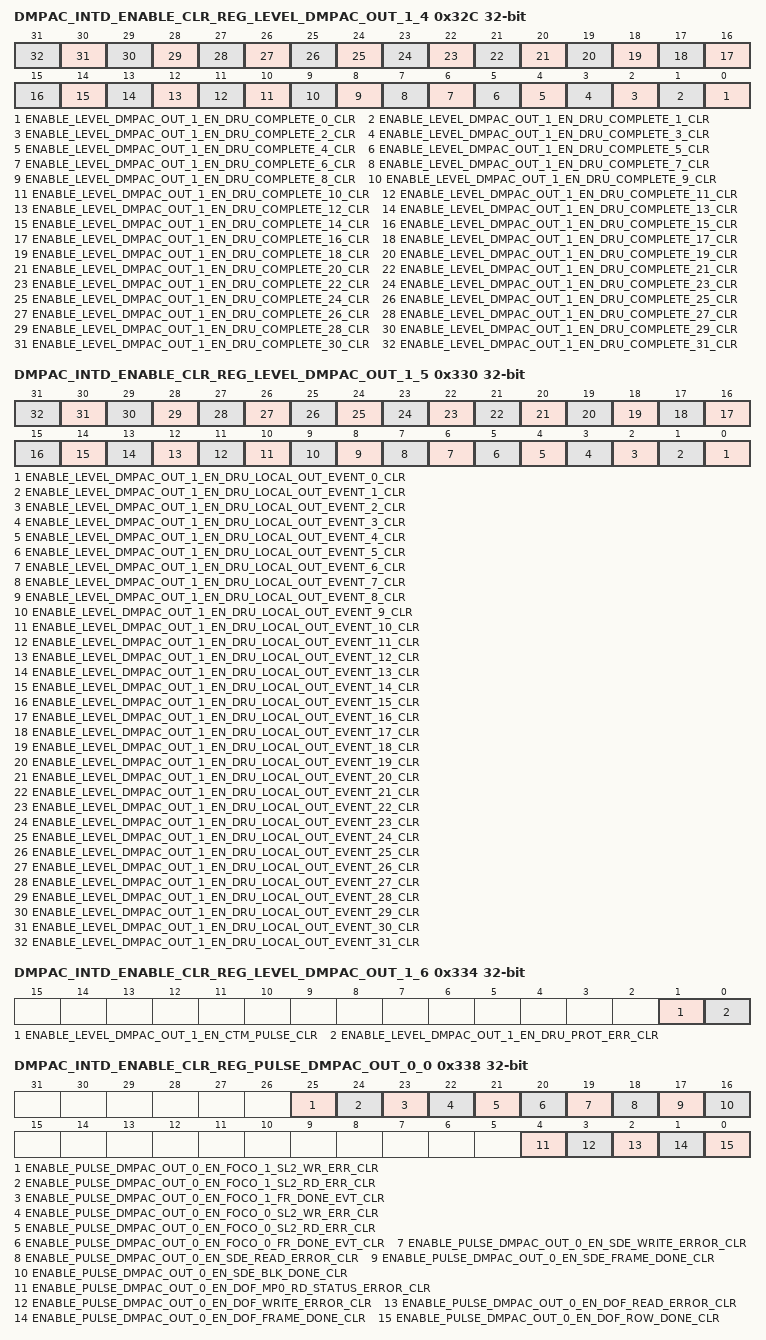
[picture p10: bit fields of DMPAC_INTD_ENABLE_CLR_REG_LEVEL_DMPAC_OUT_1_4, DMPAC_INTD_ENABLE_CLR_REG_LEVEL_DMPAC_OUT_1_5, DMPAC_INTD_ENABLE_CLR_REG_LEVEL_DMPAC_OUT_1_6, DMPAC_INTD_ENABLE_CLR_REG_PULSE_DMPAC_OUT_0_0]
0x32C DMPAC_INTD_ENABLE_CLR_REG_LEVEL_DMPAC_OUT_1_4 — Enable Clear Register 11
  [n] ENABLE_LEVEL_DMPAC_OUT_1_EN_DRU_COMPLETE_{n}_CLR (n=0..31) — Enable Clear for level_dmpac_out_1_en_dru_complete_{n} (access RW1C)
0x330 DMPAC_INTD_ENABLE_CLR_REG_LEVEL_DMPAC_OUT_1_5 — Enable Clear Register 12
  [n] ENABLE_LEVEL_DMPAC_OUT_1_EN_DRU_LOCAL_OUT_EVENT_{n}_CLR (n=0..31) — Enable Clear for level_dmpac_out_1_en_dru_local_out_event_{n} (access RW1C)
0x334 DMPAC_INTD_ENABLE_CLR_REG_LEVEL_DMPAC_OUT_1_6 — Enable Clear Register 13
  [1] ENABLE_LEVEL_DMPAC_OUT_1_EN_CTM_PULSE_CLR — Enable Clear for level_dmpac_out_1_en_ctm_pulse (access RW1C)
  [0] ENABLE_LEVEL_DMPAC_OUT_1_EN_DRU_PROT_ERR_CLR — Enable Clear for level_dmpac_out_1_en_dru_prot_err (access RW1C)
0x338 DMPAC_INTD_ENABLE_CLR_REG_PULSE_DMPAC_OUT_0_0 — Enable Clear Register 14
  [25] ENABLE_PULSE_DMPAC_OUT_0_EN_FOCO_1_SL2_WR_ERR_CLR — Enable Clear for pulse_dmpac_out_0_en_foco_1_sl2_wr_err (access RW1C)
  [24] ENABLE_PULSE_DMPAC_OUT_0_EN_FOCO_1_SL2_RD_ERR_CLR — Enable Clear for pulse_dmpac_out_0_en_foco_1_sl2_rd_err (access RW1C)
  [23] ENABLE_PULSE_DMPAC_OUT_0_EN_FOCO_1_FR_DONE_EVT_CLR — Enable Clear for pulse_dmpac_out_0_en_foco_1_fr_done_evt (access RW1C)
  [22] ENABLE_PULSE_DMPAC_OUT_0_EN_FOCO_0_SL2_WR_ERR_CLR — Enable Clear for pulse_dmpac_out_0_en_foco_0_sl2_wr_err (access RW1C)
  [21] ENABLE_PULSE_DMPAC_OUT_0_EN_FOCO_0_SL2_RD_ERR_CLR — Enable Clear for pulse_dmpac_out_0_en_foco_0_sl2_rd_err (access RW1C)
  [20] ENABLE_PULSE_DMPAC_OUT_0_EN_FOCO_0_FR_DONE_EVT_CLR — Enable Clear for pulse_dmpac_out_0_en_foco_0_fr_done_evt (access RW1C)
  [19] ENABLE_PULSE_DMPAC_OUT_0_EN_SDE_WRITE_ERROR_CLR — Enable Clear for pulse_dmpac_out_0_en_sde_write_error (access RW1C)
  [18] ENABLE_PULSE_DMPAC_OUT_0_EN_SDE_READ_ERROR_CLR — Enable Clear for pulse_dmpac_out_0_en_sde_read_error (access RW1C)
  [17] ENABLE_PULSE_DMPAC_OUT_0_EN_SDE_FRAME_DONE_CLR — Enable Clear for pulse_dmpac_out_0_en_sde_frame_done (access RW1C)
  [16] ENABLE_PULSE_DMPAC_OUT_0_EN_SDE_BLK_DONE_CLR — Enable Clear for pulse_dmpac_out_0_en_sde_blk_done (access RW1C)
  [4] ENABLE_PULSE_DMPAC_OUT_0_EN_DOF_MP0_RD_STATUS_ERROR_CLR — Enable Clear for pulse_dmpac_out_0_en_dof_mp0_rd_status_error (access RW1C)
  [3] ENABLE_PULSE_DMPAC_OUT_0_EN_DOF_WRITE_ERROR_CLR — Enable Clear for pulse_dmpac_out_0_en_dof_write_error (access RW1C)
  [2] ENABLE_PULSE_DMPAC_OUT_0_EN_DOF_READ_ERROR_CLR — Enable Clear for pulse_dmpac_out_0_en_dof_read_error (access RW1C)
  [1] ENABLE_PULSE_DMPAC_OUT_0_EN_DOF_FRAME_DONE_CLR — Enable Clear for pulse_dmpac_out_0_en_dof_frame_done (access RW1C)
  [0] ENABLE_PULSE_DMPAC_OUT_0_EN_DOF_ROW_DONE_CLR — Enable Clear for pulse_dmpac_out_0_en_dof_row_done (access RW1C)
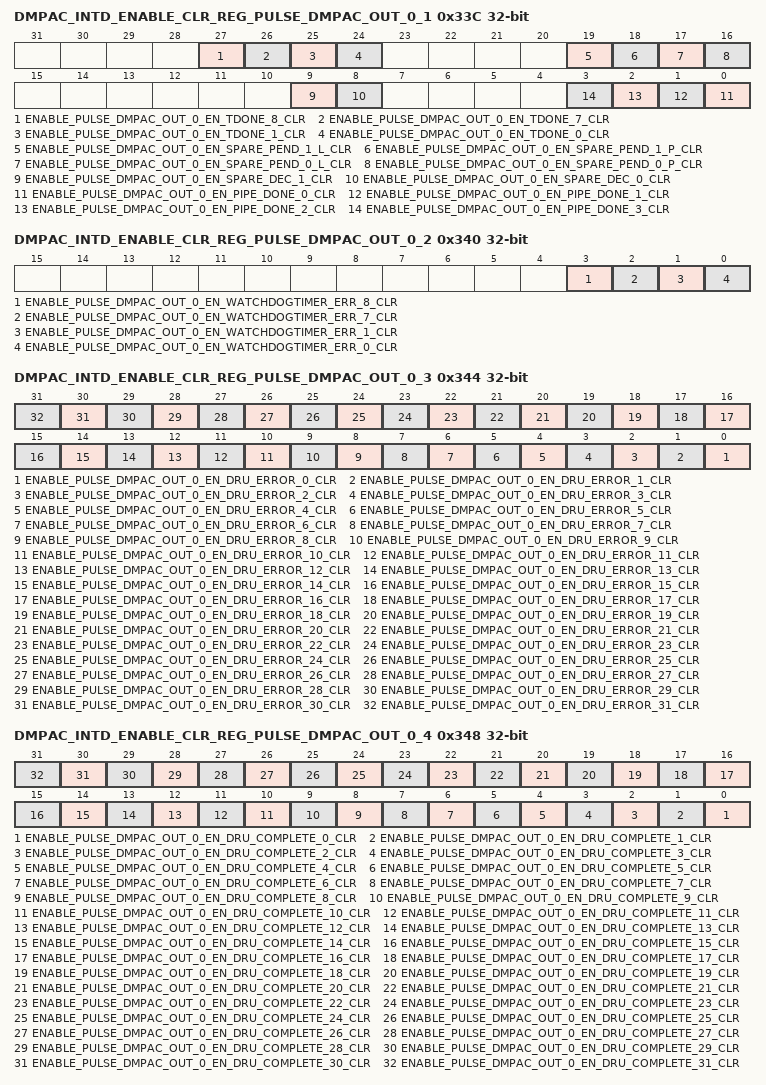
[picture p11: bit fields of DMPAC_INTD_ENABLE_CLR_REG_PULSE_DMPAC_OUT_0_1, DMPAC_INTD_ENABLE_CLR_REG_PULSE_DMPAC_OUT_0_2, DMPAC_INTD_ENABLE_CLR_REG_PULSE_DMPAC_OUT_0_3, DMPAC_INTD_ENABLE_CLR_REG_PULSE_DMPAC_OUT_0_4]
0x33C DMPAC_INTD_ENABLE_CLR_REG_PULSE_DMPAC_OUT_0_1 — Enable Clear Register 15
  [27] ENABLE_PULSE_DMPAC_OUT_0_EN_TDONE_8_CLR — Enable Clear for pulse_dmpac_out_0_en_tdone_8 (access RW1C)
  [26] ENABLE_PULSE_DMPAC_OUT_0_EN_TDONE_7_CLR — Enable Clear for pulse_dmpac_out_0_en_tdone_7 (access RW1C)
  [25] ENABLE_PULSE_DMPAC_OUT_0_EN_TDONE_1_CLR — Enable Clear for pulse_dmpac_out_0_en_tdone_1 (access RW1C)
  [24] ENABLE_PULSE_DMPAC_OUT_0_EN_TDONE_0_CLR — Enable Clear for pulse_dmpac_out_0_en_tdone_0 (access RW1C)
  [19] ENABLE_PULSE_DMPAC_OUT_0_EN_SPARE_PEND_1_L_CLR — Enable Clear for pulse_dmpac_out_0_en_spare_pend_1_l (access RW1C)
  [18] ENABLE_PULSE_DMPAC_OUT_0_EN_SPARE_PEND_1_P_CLR — Enable Clear for pulse_dmpac_out_0_en_spare_pend_1_p (access RW1C)
  [17] ENABLE_PULSE_DMPAC_OUT_0_EN_SPARE_PEND_0_L_CLR — Enable Clear for pulse_dmpac_out_0_en_spare_pend_0_l (access RW1C)
  [16] ENABLE_PULSE_DMPAC_OUT_0_EN_SPARE_PEND_0_P_CLR — Enable Clear for pulse_dmpac_out_0_en_spare_pend_0_p (access RW1C)
  [9] ENABLE_PULSE_DMPAC_OUT_0_EN_SPARE_DEC_1_CLR — Enable Clear for pulse_dmpac_out_0_en_spare_dec_1 (access RW1C)
  [8] ENABLE_PULSE_DMPAC_OUT_0_EN_SPARE_DEC_0_CLR — Enable Clear for pulse_dmpac_out_0_en_spare_dec_0 (access RW1C)
  [n] ENABLE_PULSE_DMPAC_OUT_0_EN_PIPE_DONE_{n}_CLR (n=0..3) — Enable Clear for pulse_dmpac_out_0_en_pipe_done_{n} (access RW1C)
0x340 DMPAC_INTD_ENABLE_CLR_REG_PULSE_DMPAC_OUT_0_2 — Enable Clear Register 16
  [3] ENABLE_PULSE_DMPAC_OUT_0_EN_WATCHDOGTIMER_ERR_8_CLR — Enable Clear for pulse_dmpac_out_0_en_watchdogtimer_err_8 (access RW1C)
  [2] ENABLE_PULSE_DMPAC_OUT_0_EN_WATCHDOGTIMER_ERR_7_CLR — Enable Clear for pulse_dmpac_out_0_en_watchdogtimer_err_7 (access RW1C)
  [1] ENABLE_PULSE_DMPAC_OUT_0_EN_WATCHDOGTIMER_ERR_1_CLR — Enable Clear for pulse_dmpac_out_0_en_watchdogtimer_err_1 (access RW1C)
  [0] ENABLE_PULSE_DMPAC_OUT_0_EN_WATCHDOGTIMER_ERR_0_CLR — Enable Clear for pulse_dmpac_out_0_en_watchdogtimer_err_0 (access RW1C)
0x344 DMPAC_INTD_ENABLE_CLR_REG_PULSE_DMPAC_OUT_0_3 — Enable Clear Register 17
  [n] ENABLE_PULSE_DMPAC_OUT_0_EN_DRU_ERROR_{n}_CLR (n=0..31) — Enable Clear for pulse_dmpac_out_0_en_dru_error_{n} (access RW1C)
0x348 DMPAC_INTD_ENABLE_CLR_REG_PULSE_DMPAC_OUT_0_4 — Enable Clear Register 18
  [n] ENABLE_PULSE_DMPAC_OUT_0_EN_DRU_COMPLETE_{n}_CLR (n=0..31) — Enable Clear for pulse_dmpac_out_0_en_dru_complete_{n} (access RW1C)
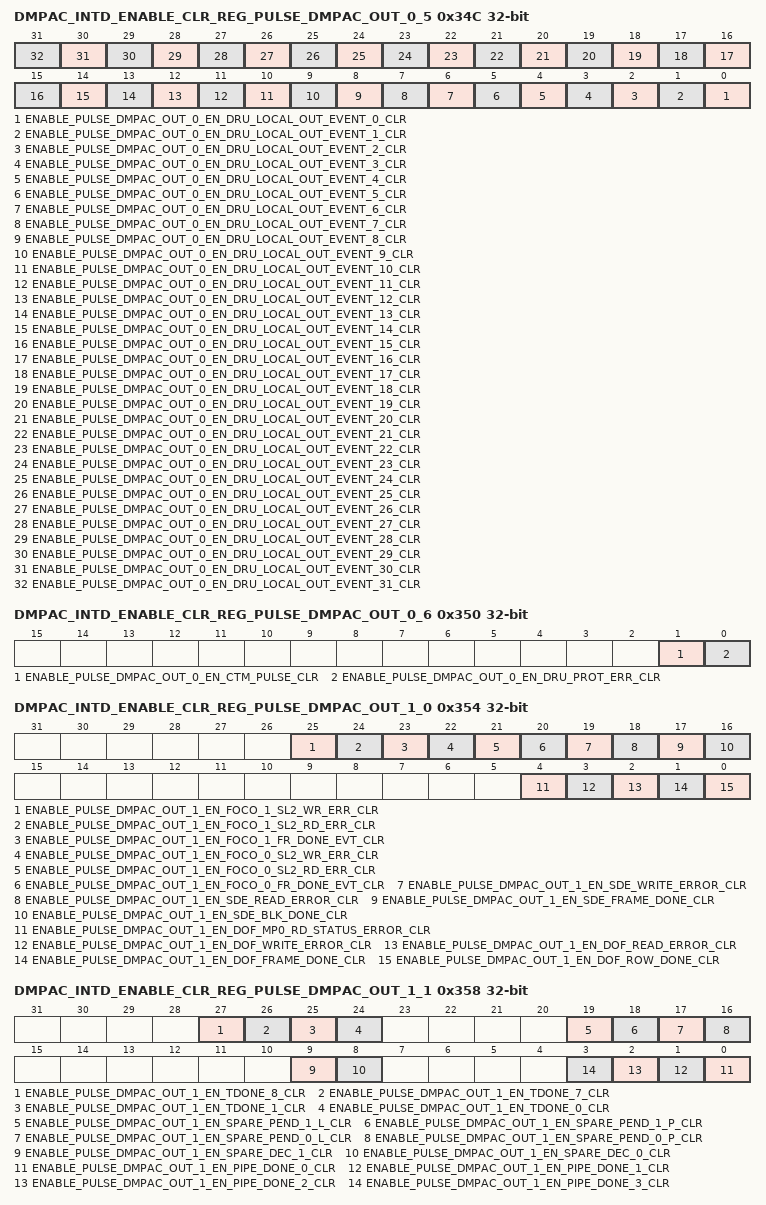
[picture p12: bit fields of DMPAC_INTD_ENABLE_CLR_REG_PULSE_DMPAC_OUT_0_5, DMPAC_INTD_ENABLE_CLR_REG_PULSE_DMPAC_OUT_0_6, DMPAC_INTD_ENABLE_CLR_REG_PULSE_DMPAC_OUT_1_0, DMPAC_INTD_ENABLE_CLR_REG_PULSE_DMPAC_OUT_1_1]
0x34C DMPAC_INTD_ENABLE_CLR_REG_PULSE_DMPAC_OUT_0_5 — Enable Clear Register 19
  [n] ENABLE_PULSE_DMPAC_OUT_0_EN_DRU_LOCAL_OUT_EVENT_{n}_CLR (n=0..31) — Enable Clear for pulse_dmpac_out_0_en_dru_local_out_event_{n} (access RW1C)
0x350 DMPAC_INTD_ENABLE_CLR_REG_PULSE_DMPAC_OUT_0_6 — Enable Clear Register 20
  [1] ENABLE_PULSE_DMPAC_OUT_0_EN_CTM_PULSE_CLR — Enable Clear for pulse_dmpac_out_0_en_ctm_pulse (access RW1C)
  [0] ENABLE_PULSE_DMPAC_OUT_0_EN_DRU_PROT_ERR_CLR — Enable Clear for pulse_dmpac_out_0_en_dru_prot_err (access RW1C)
0x354 DMPAC_INTD_ENABLE_CLR_REG_PULSE_DMPAC_OUT_1_0 — Enable Clear Register 21
  [25] ENABLE_PULSE_DMPAC_OUT_1_EN_FOCO_1_SL2_WR_ERR_CLR — Enable Clear for pulse_dmpac_out_1_en_foco_1_sl2_wr_err (access RW1C)
  [24] ENABLE_PULSE_DMPAC_OUT_1_EN_FOCO_1_SL2_RD_ERR_CLR — Enable Clear for pulse_dmpac_out_1_en_foco_1_sl2_rd_err (access RW1C)
  [23] ENABLE_PULSE_DMPAC_OUT_1_EN_FOCO_1_FR_DONE_EVT_CLR — Enable Clear for pulse_dmpac_out_1_en_foco_1_fr_done_evt (access RW1C)
  [22] ENABLE_PULSE_DMPAC_OUT_1_EN_FOCO_0_SL2_WR_ERR_CLR — Enable Clear for pulse_dmpac_out_1_en_foco_0_sl2_wr_err (access RW1C)
  [21] ENABLE_PULSE_DMPAC_OUT_1_EN_FOCO_0_SL2_RD_ERR_CLR — Enable Clear for pulse_dmpac_out_1_en_foco_0_sl2_rd_err (access RW1C)
  [20] ENABLE_PULSE_DMPAC_OUT_1_EN_FOCO_0_FR_DONE_EVT_CLR — Enable Clear for pulse_dmpac_out_1_en_foco_0_fr_done_evt (access RW1C)
  [19] ENABLE_PULSE_DMPAC_OUT_1_EN_SDE_WRITE_ERROR_CLR — Enable Clear for pulse_dmpac_out_1_en_sde_write_error (access RW1C)
  [18] ENABLE_PULSE_DMPAC_OUT_1_EN_SDE_READ_ERROR_CLR — Enable Clear for pulse_dmpac_out_1_en_sde_read_error (access RW1C)
  [17] ENABLE_PULSE_DMPAC_OUT_1_EN_SDE_FRAME_DONE_CLR — Enable Clear for pulse_dmpac_out_1_en_sde_frame_done (access RW1C)
  [16] ENABLE_PULSE_DMPAC_OUT_1_EN_SDE_BLK_DONE_CLR — Enable Clear for pulse_dmpac_out_1_en_sde_blk_done (access RW1C)
  [4] ENABLE_PULSE_DMPAC_OUT_1_EN_DOF_MP0_RD_STATUS_ERROR_CLR — Enable Clear for pulse_dmpac_out_1_en_dof_mp0_rd_status_error (access RW1C)
  [3] ENABLE_PULSE_DMPAC_OUT_1_EN_DOF_WRITE_ERROR_CLR — Enable Clear for pulse_dmpac_out_1_en_dof_write_error (access RW1C)
  [2] ENABLE_PULSE_DMPAC_OUT_1_EN_DOF_READ_ERROR_CLR — Enable Clear for pulse_dmpac_out_1_en_dof_read_error (access RW1C)
  [1] ENABLE_PULSE_DMPAC_OUT_1_EN_DOF_FRAME_DONE_CLR — Enable Clear for pulse_dmpac_out_1_en_dof_frame_done (access RW1C)
  [0] ENABLE_PULSE_DMPAC_OUT_1_EN_DOF_ROW_DONE_CLR — Enable Clear for pulse_dmpac_out_1_en_dof_row_done (access RW1C)
0x358 DMPAC_INTD_ENABLE_CLR_REG_PULSE_DMPAC_OUT_1_1 — Enable Clear Register 22
  [27] ENABLE_PULSE_DMPAC_OUT_1_EN_TDONE_8_CLR — Enable Clear for pulse_dmpac_out_1_en_tdone_8 (access RW1C)
  [26] ENABLE_PULSE_DMPAC_OUT_1_EN_TDONE_7_CLR — Enable Clear for pulse_dmpac_out_1_en_tdone_7 (access RW1C)
  [25] ENABLE_PULSE_DMPAC_OUT_1_EN_TDONE_1_CLR — Enable Clear for pulse_dmpac_out_1_en_tdone_1 (access RW1C)
  [24] ENABLE_PULSE_DMPAC_OUT_1_EN_TDONE_0_CLR — Enable Clear for pulse_dmpac_out_1_en_tdone_0 (access RW1C)
  [19] ENABLE_PULSE_DMPAC_OUT_1_EN_SPARE_PEND_1_L_CLR — Enable Clear for pulse_dmpac_out_1_en_spare_pend_1_l (access RW1C)
  [18] ENABLE_PULSE_DMPAC_OUT_1_EN_SPARE_PEND_1_P_CLR — Enable Clear for pulse_dmpac_out_1_en_spare_pend_1_p (access RW1C)
  [17] ENABLE_PULSE_DMPAC_OUT_1_EN_SPARE_PEND_0_L_CLR — Enable Clear for pulse_dmpac_out_1_en_spare_pend_0_l (access RW1C)
  [16] ENABLE_PULSE_DMPAC_OUT_1_EN_SPARE_PEND_0_P_CLR — Enable Clear for pulse_dmpac_out_1_en_spare_pend_0_p (access RW1C)
  [9] ENABLE_PULSE_DMPAC_OUT_1_EN_SPARE_DEC_1_CLR — Enable Clear for pulse_dmpac_out_1_en_spare_dec_1 (access RW1C)
  [8] ENABLE_PULSE_DMPAC_OUT_1_EN_SPARE_DEC_0_CLR — Enable Clear for pulse_dmpac_out_1_en_spare_dec_0 (access RW1C)
  [n] ENABLE_PULSE_DMPAC_OUT_1_EN_PIPE_DONE_{n}_CLR (n=0..3) — Enable Clear for pulse_dmpac_out_1_en_pipe_done_{n} (access RW1C)
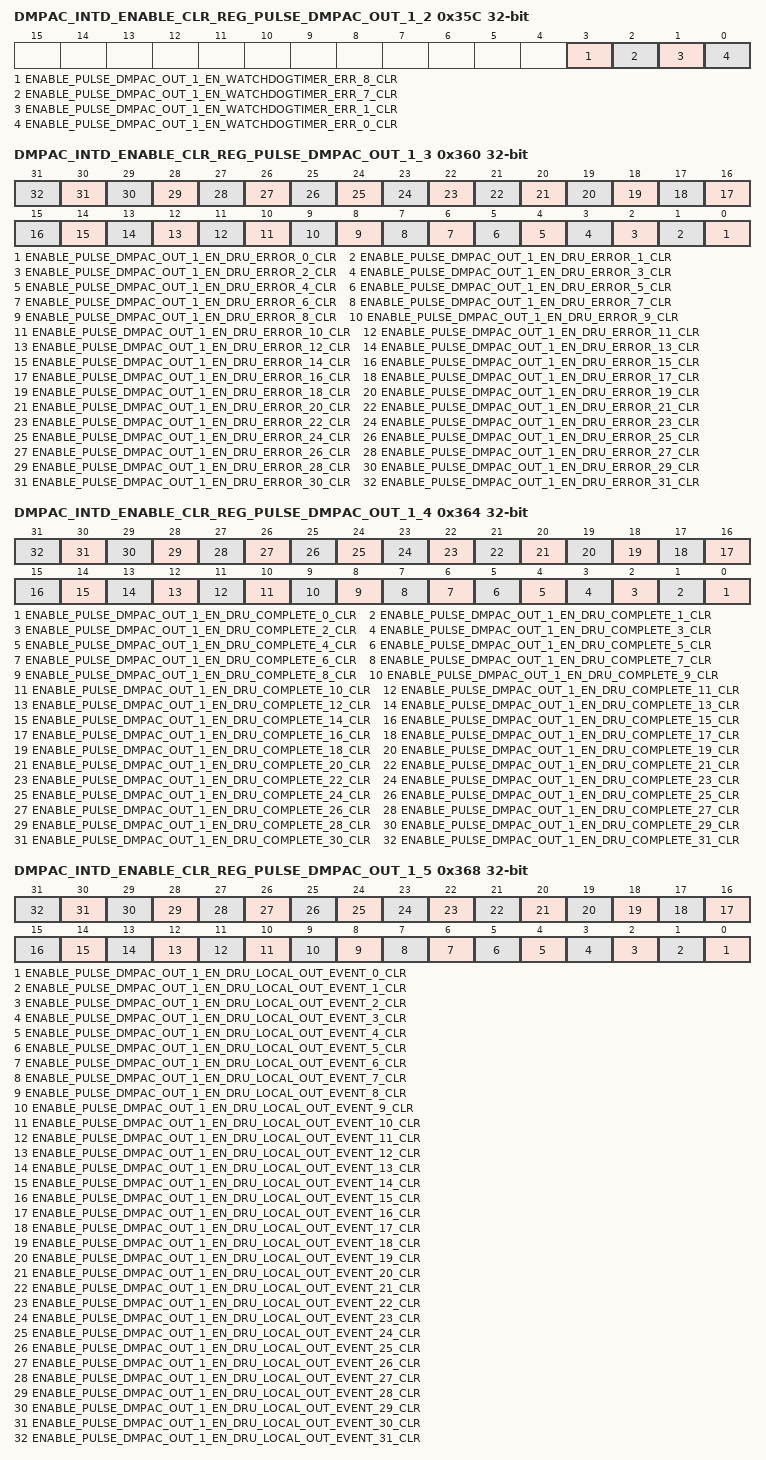
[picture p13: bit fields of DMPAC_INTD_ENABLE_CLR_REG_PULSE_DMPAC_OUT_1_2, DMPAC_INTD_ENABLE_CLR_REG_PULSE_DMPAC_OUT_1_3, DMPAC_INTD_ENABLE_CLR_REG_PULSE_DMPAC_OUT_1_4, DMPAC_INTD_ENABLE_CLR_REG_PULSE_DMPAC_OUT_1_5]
0x35C DMPAC_INTD_ENABLE_CLR_REG_PULSE_DMPAC_OUT_1_2 — Enable Clear Register 23
  [3] ENABLE_PULSE_DMPAC_OUT_1_EN_WATCHDOGTIMER_ERR_8_CLR — Enable Clear for pulse_dmpac_out_1_en_watchdogtimer_err_8 (access RW1C)
  [2] ENABLE_PULSE_DMPAC_OUT_1_EN_WATCHDOGTIMER_ERR_7_CLR — Enable Clear for pulse_dmpac_out_1_en_watchdogtimer_err_7 (access RW1C)
  [1] ENABLE_PULSE_DMPAC_OUT_1_EN_WATCHDOGTIMER_ERR_1_CLR — Enable Clear for pulse_dmpac_out_1_en_watchdogtimer_err_1 (access RW1C)
  [0] ENABLE_PULSE_DMPAC_OUT_1_EN_WATCHDOGTIMER_ERR_0_CLR — Enable Clear for pulse_dmpac_out_1_en_watchdogtimer_err_0 (access RW1C)
0x360 DMPAC_INTD_ENABLE_CLR_REG_PULSE_DMPAC_OUT_1_3 — Enable Clear Register 24
  [n] ENABLE_PULSE_DMPAC_OUT_1_EN_DRU_ERROR_{n}_CLR (n=0..31) — Enable Clear for pulse_dmpac_out_1_en_dru_error_{n} (access RW1C)
0x364 DMPAC_INTD_ENABLE_CLR_REG_PULSE_DMPAC_OUT_1_4 — Enable Clear Register 25
  [n] ENABLE_PULSE_DMPAC_OUT_1_EN_DRU_COMPLETE_{n}_CLR (n=0..31) — Enable Clear for pulse_dmpac_out_1_en_dru_complete_{n} (access RW1C)
0x368 DMPAC_INTD_ENABLE_CLR_REG_PULSE_DMPAC_OUT_1_5 — Enable Clear Register 26
  [n] ENABLE_PULSE_DMPAC_OUT_1_EN_DRU_LOCAL_OUT_EVENT_{n}_CLR (n=0..31) — Enable Clear for pulse_dmpac_out_1_en_dru_local_out_event_{n} (access RW1C)
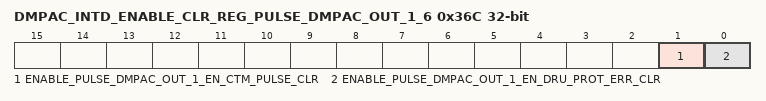
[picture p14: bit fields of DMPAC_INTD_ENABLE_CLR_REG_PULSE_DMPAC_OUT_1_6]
0x36C DMPAC_INTD_ENABLE_CLR_REG_PULSE_DMPAC_OUT_1_6 — Enable Clear Register 27
  [1] ENABLE_PULSE_DMPAC_OUT_1_EN_CTM_PULSE_CLR — Enable Clear for pulse_dmpac_out_1_en_ctm_pulse (access RW1C)
  [0] ENABLE_PULSE_DMPAC_OUT_1_EN_DRU_PROT_ERR_CLR — Enable Clear for pulse_dmpac_out_1_en_dru_prot_err (access RW1C)
